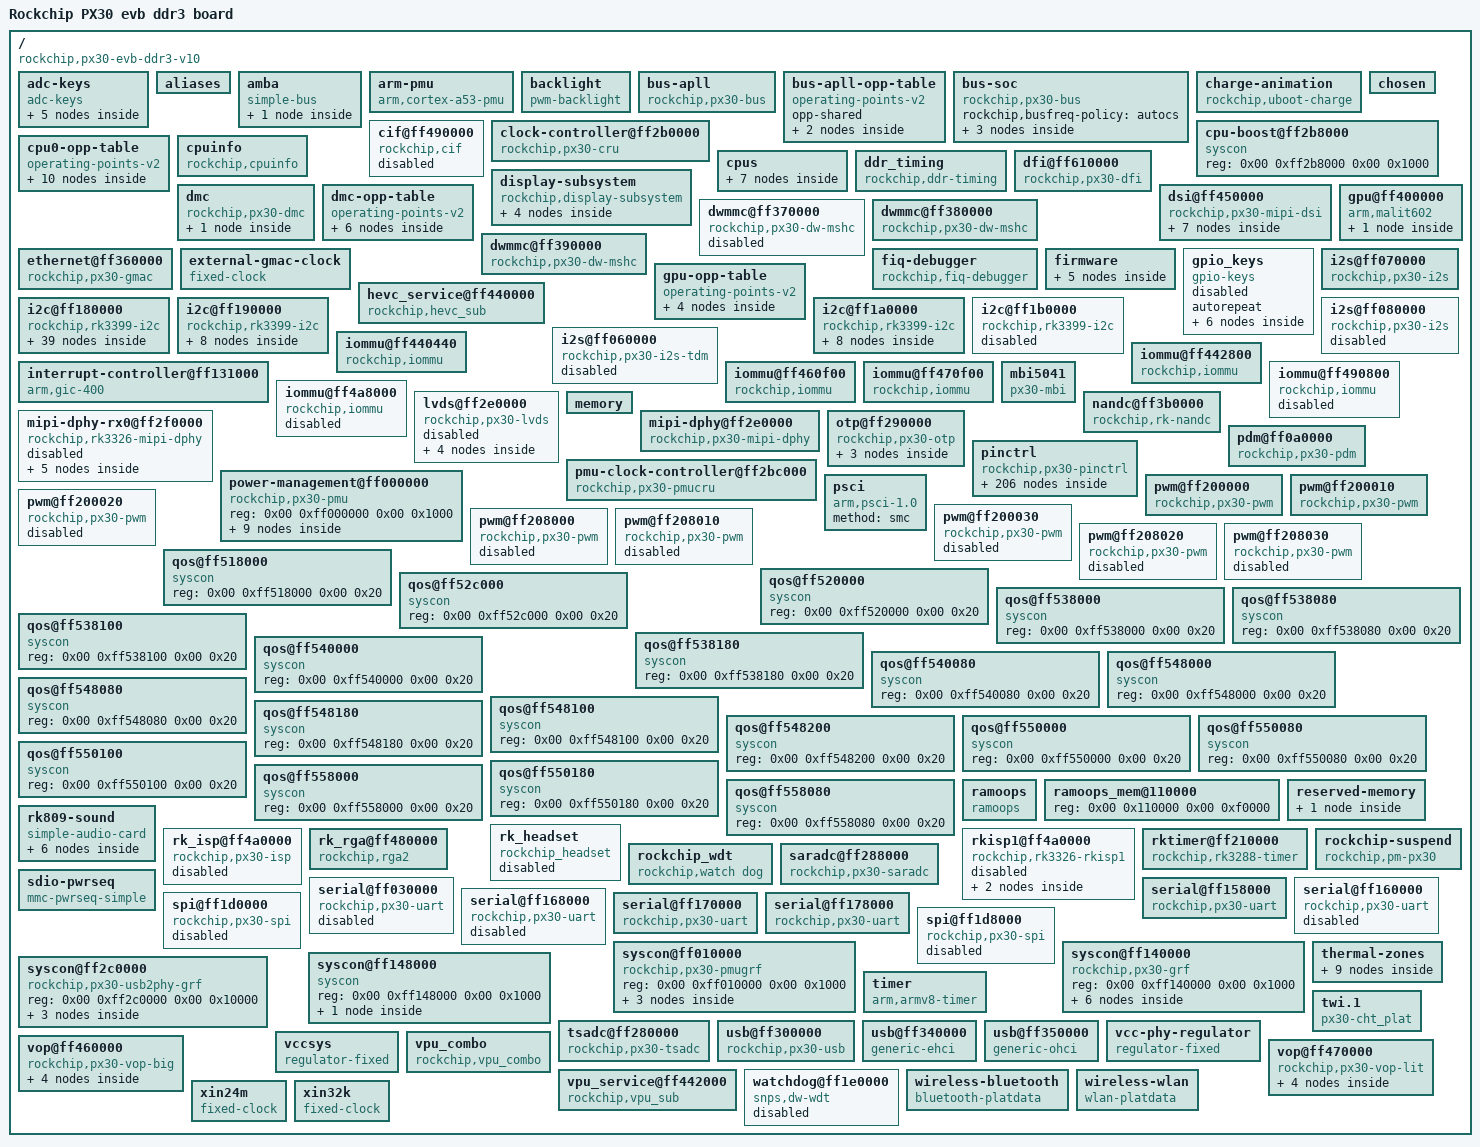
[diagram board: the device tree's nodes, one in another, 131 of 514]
/dts-v1/;

/memreserve/	0x0000000008081000 0x0000000000013000;
/memreserve/	0x0000000008097000 0x0000000000168978;
/ {
	#address-cells = <0x02>;
	#size-cells = <0x02>;
	compatible = "rockchip,px30-evb-ddr3-v10", "rockchip,px30";
	interrupt-parent = <0x01>;
	model = "Rockchip PX30 evb ddr3 board";
	serial-number = "XXXXXXXXXXXXXX";

	adc-keys {
		compatible = "adc-keys";
		io-channel-names = "buttons";
		io-channels = <0xc6 0x02>;
		keyup-threshold-microvolt = <0x1b7740>;
		poll-interval = <0x64>;

		esc-key {
			label = "esc";
			linux,code = <0x01>;
			press-threshold-microvolt = <0x13fd30>;
		};

		home-key {
			label = "home";
			linux,code = <0x66>;
			press-threshold-microvolt = <0x98580>;
		};

		menu-key {
			label = "menu";
			linux,code = <0x8b>;
			press-threshold-microvolt = <0xf0f78>;
		};

		vol-down-key {
			label = "volume down";
			linux,code = <0x72>;
			press-threshold-microvolt = <0x493e0>;
		};

		vol-up-key {
			label = "volume up";
			linux,code = <0x73>;
			press-threshold-microvolt = <0x4268>;
		};
	};

	aliases {
		ethernet0 = "/ethernet@ff360000";
		i2c0 = "/i2c@ff180000";
		i2c1 = "/i2c@ff190000";
		i2c2 = "/i2c@ff1a0000";
		i2c3 = "/i2c@ff1b0000";
		serial0 = "/serial@ff030000";
		serial1 = "/serial@ff158000";
		serial2 = "/serial@ff160000";
		serial3 = "/serial@ff168000";
		serial4 = "/serial@ff170000";
		serial5 = "/serial@ff178000";
		spi0 = "/spi@ff1d0000";
		spi1 = "/spi@ff1d8000";
	};

	amba {
		#address-cells = <0x02>;
		#size-cells = <0x02>;
		compatible = "simple-bus";
		ranges;

		dmac@ff240000 {
			#dma-cells = <0x01>;
			clock-names = "apb_pclk";
			clocks = <0x02 0xbb>;
			compatible = "arm,pl330", "arm,primecell";
			interrupts = <0x00 0x01 0x04 0x00 0x02 0x04>;
			peripherals-req-type-burst;
			phandle = <0x2c>;
			reg = <0x00 0xff240000 0x00 0x4000>;
		};
	};

	arm-pmu {
		compatible = "arm,cortex-a53-pmu";
		interrupt-affinity = <0x09 0x0a 0x0b 0x0c>;
		interrupts = <0x00 0x64 0x04 0x00 0x65 0x04 0x00 0x66 0x04 0x00 0x67 0x04>;
	};

	backlight {
		brightness-levels = <0x00 0x01 0x02 0x03 0x04 0x05 0x06 0x07 0x08 0x09 0x0a 0x0b 0x0c 0x0d 0x0e 0x0f 0x10 0x11 0x12 0x13 0x14 0x15 0x16 0x17 0x18 0x19 0x1a 0x1b 0x1c 0x1d 0x1e 0x1f 0x20 0x21 0x22 0x23 0x24 0x25 0x26 0x27 0x28 0x29 0x2a 0x2b 0x2c 0x2d 0x2e 0x2f 0x30 0x31 0x32 0x33 0x34 0x35 0x36 0x37 0x38 0x39 0x3a 0x3b 0x3c 0x3d 0x3e 0x3f 0x40 0x41 0x42 0x43 0x44 0x45 0x46 0x47 0x48 0x49 0x4a 0x4b 0x4c 0x4d 0x4e 0x4f 0x50 0x51 0x52 0x53 0x54 0x55 0x56 0x57 0x58 0x59 0x5a 0x5b 0x5c 0x5d 0x5e 0x5f 0x60 0x61 0x62 0x63 0x64 0x65 0x66 0x67 0x68 0x69 0x6a 0x6b 0x6c 0x6d 0x6e 0x6f 0x70 0x71 0x72 0x73 0x74 0x75 0x76 0x77 0x78 0x79 0x7a 0x7b 0x7c 0x7d 0x7e 0x7f 0x80 0x81 0x82 0x83 0x84 0x85 0x86 0x87 0x88 0x89 0x8a 0x8b 0x8c 0x8d 0x8e 0x8f 0x90 0x91 0x92 0x93 0x94 0x95 0x96 0x97 0x98 0x99 0x9a 0x9b 0x9c 0x9d 0x9e 0x9f 0xa0 0xa1 0xa2 0xa3 0xa4 0xa5 0xa6 0xa7 0xa8 0xa9 0xaa 0xab 0xac 0xad 0xae 0xaf 0xb0 0xb1 0xb2 0xb3 0xb4 0xb5 0xb6 0xb7 0xb8 0xb9 0xba 0xbb 0xbc 0xbd 0xbe 0xbf 0xc0 0xc1 0xc2 0xc3 0xc4 0xc5 0xc6 0xc7 0xc8 0xc9 0xca 0xcb 0xcc 0xcd 0xce 0xcf 0xd0 0xd1 0xd2 0xd3 0xd4 0xd5 0xd6 0xd7 0xd8 0xd9 0xda 0xdb 0xdc 0xdd 0xde 0xdf 0xe0 0xe1 0xe2 0xe3 0xe4 0xe5 0xe6 0xe7 0xe8 0xe9 0xea 0xeb 0xec 0xed 0xee 0xef 0xf0 0xf1 0xf2 0xf3 0xf4 0xf5 0xf6 0xf7 0xf8 0xf9 0xfa 0xfb 0xfc 0xfd 0xfe 0xff>;
		compatible = "pwm-backlight";
		default-brightness-level = <0x14>;
		phandle = <0xa5>;
		pwms = <0xc7 0x00 0x61a8 0x00>;
	};

	bus-apll {
		bus-supply = <0x0e>;
		clock-names = "bus";
		clocks = <0x02 0x01>;
		compatible = "rockchip,px30-bus";
		operating-points-v2 = <0x0d>;
		rockchip,busfreq-policy = "clkfreq";
		status = "okay";
	};

	bus-apll-opp-table {
		compatible = "operating-points-v2";
		opp-shared;
		phandle = <0x0d>;

		opp-1008000000 {
			opp-hz = <0x00 0x3c14dc00>;
			opp-microvolt = <0xe7ef0>;
		};

		opp-1512000000 {
			opp-hz = <0x00 0x5a1f4a00>;
			opp-microvolt = <0xf4240>;
		};
	};

	bus-soc {
		compatible = "rockchip,px30-bus";
		rockchip,busfreq-policy = "autocs";

		soc-bus0 {
			bus-id = <0x00>;
			enable-msk = <0x40f7>;
			status = "disabled";
			timer-us = <0x14>;
		};

		soc-bus1 {
			bus-id = <0x01>;
			enable-msk = <0x40bf>;
			status = "disabled";
			timer-us = <0xc8>;
		};

		soc-bus2 {
			bus-id = <0x02>;
			enable-msk = <0x4007>;
			status = "disabled";
			timer-us = <0xc8>;
		};
	};

	charge-animation {
		compatible = "rockchip,uboot-charge";
		rockchip,android-charge-on = <0x01>;
		rockchip,screen-on-voltage = <0xe10>;
		rockchip,uboot-charge-on = <0x00>;
		rockchip,uboot-low-power-voltage = <0xdac>;
		status = "okay";
	};

	chosen {
		bootargs = "storagemedia=emmc androidboot.mode=emmc androidboot.oem_unlocked=0 androidboot.slot_suffix= androidboot.serialno=XXXXXXXXXXXXXX buildvariant=userdebug loglevel=7 earlyprintk=uart8250,mmio32,0xff160000 swiotlb=1 console=ttyFIQ0 androidboot.baseband=N/A androidboot.veritymode=enforcing androidboot.hardware=rk30board androidboot.console=ttyFIQ0 init=/init kpti=0 androidboot.selinux=permissive";
		linux,initrd-end = <0x00 0x81ff978>;
		linux,initrd-start = <0x00 0x8097000>;
	};

	cif@ff490000 {
		clock-names = "aclk_cif0", "hclk_cif0", "pclk_cif", "cif0_out";
		clocks = <0x02 0xb3 0x02 0xf9 0x02 0x160 0x02 0x34>;
		compatible = "rockchip,cif";
		interrupts = <0x00 0x45 0x04>;
		iommus = <0xb0>;
		pinctrl-0 = <0xaf>;
		pinctrl-names = "cif_pin_all";
		power-domains = <0x8c 0x0d>;
		reg = <0x00 0xff490000 0x00 0x200>;
		reset-names = "rst_cif_a", "rst_cif_h", "rst_cif_pclkin";
		resets = <0x02 0x2c 0x02 0x2d 0x02 0x2e>;
		status = "disabled";
	};

	clock-controller@ff2b0000 {
		#clock-cells = <0x01>;
		#reset-cells = <0x01>;
		compatible = "rockchip,px30-cru";
		phandle = <0x02>;
		reg = <0x00 0xff2b0000 0x00 0x1000>;
		rockchip,boost = <0x8a>;
		rockchip,grf = <0x87>;
	};

	cpu-boost@ff2b8000 {
		compatible = "syscon";
		phandle = <0x8a>;
		reg = <0x00 0xff2b8000 0x00 0x1000>;
	};

	cpu0-opp-table {
		clocks = <0x02 0x01>;
		compatible = "operating-points-v2";
		nvmem-cell-names = "cpu_leakage", "performance";
		nvmem-cells = <0x07 0x08>;
		opp-shared;
		phandle = <0x03>;
		rockchip,avs = <0x01>;
		rockchip,avs-scale = <0x04>;
		rockchip,bin-scaling-sel = <0x00 0x0d 0x01 0x0f 0x02 0x12>;
		rockchip,evb-irdrop = <0x61a8>;
		rockchip,max-volt = <0x149970>;
		rockchip,pvtm-ch = <0x00 0x00>;
		rockchip,pvtm-error = <0x3e8>;
		rockchip,pvtm-freq = <0x639c0>;
		rockchip,pvtm-number = <0x0a>;
		rockchip,pvtm-ref-temp = <0x28>;
		rockchip,pvtm-sample-time = <0x3e8>;
		rockchip,pvtm-temp-prop = <0xffffffc8 0xffffffc8>;
		rockchip,pvtm-volt = <0xf4240>;
		rockchip,pvtm-voltage-sel = <0x00 0xc350 0x00 0xc351 0xd2f0 0x01 0xd2f1 0xea60 0x02 0xea61 0x1869f 0x03>;
		rockchip,thermal-zone = "soc-thermal";

		opp-1008000000 {
			clock-latency-ns = <0x9c40>;
			opp-hz = <0x00 0x3c14dc00>;
			opp-microvolt = <0x11edd8 0x11edd8 0x149970>;
			opp-microvolt-L0 = <0x11edd8 0x11edd8 0x149970>;
			opp-microvolt-L1 = <0x112a88 0x112a88 0x149970>;
			opp-microvolt-L2 = <0x112a88 0x112a88 0x149970>;
			opp-microvolt-L3 = <0x100590 0x100590 0x149970>;
		};

		opp-1104000000 {
			clock-latency-ns = <0x9c40>;
			opp-hz = <0x00 0x41cdb400>;
			opp-microvolt = <0x13d620 0x13d620 0x149970>;
			opp-microvolt-L0 = <0x13d620 0x13d620 0x149970>;
			opp-microvolt-L1 = <0x137478 0x137478 0x149970>;
			opp-microvolt-L2 = <0x1312d0 0x1312d0 0x149970>;
			opp-microvolt-L3 = <0x124f80 0x124f80 0x149970>;
		};

		opp-1200000000 {
			clock-latency-ns = <0x9c40>;
			opp-hz = <0x00 0x47868c00>;
			opp-microvolt = <0x13d620 0x13d620 0x149970>;
			opp-microvolt-L0 = <0x13d620 0x13d620 0x149970>;
			opp-microvolt-L1 = <0x137478 0x137478 0x149970>;
			opp-microvolt-L2 = <0x1312d0 0x1312d0 0x149970>;
			opp-microvolt-L3 = <0x124f80 0x124f80 0x149970>;
		};

		opp-1248000000 {
			clock-latency-ns = <0x9c40>;
			opp-hz = <0x00 0x4a62f800>;
			opp-microvolt = <0x149970 0x149970 0x149970>;
			opp-microvolt-L0 = <0x149970 0x149970 0x149970>;
			opp-microvolt-L1 = <0x13d620 0x13d620 0x149970>;
			opp-microvolt-L2 = <0x137478 0x137478 0x149970>;
			opp-microvolt-L3 = <0x12b128 0x12b128 0x149970>;
		};

		opp-1296000000 {
			clock-latency-ns = <0x9c40>;
			opp-hz = <0x00 0x4d3f6400>;
			opp-microvolt = <0x149970 0x149970 0x149970>;
			opp-microvolt-L0 = <0x149970 0x149970 0x149970>;
			opp-microvolt-L1 = <0x149970 0x149970 0x149970>;
			opp-microvolt-L2 = <0x13d620 0x13d620 0x149970>;
			opp-microvolt-L3 = <0x1312d0 0x1312d0 0x149970>;
		};

		opp-1416000000 {
			clock-latency-ns = <0x9c40>;
			opp-hz = <0x00 0x54667200>;
			opp-microvolt = <0x149970 0x149970 0x149970>;
			opp-microvolt-L0 = <0x149970 0x149970 0x149970>;
			opp-microvolt-L1 = <0x149970 0x149970 0x149970>;
			opp-microvolt-L2 = <0x13d620 0x13d620 0x149970>;
			opp-microvolt-L3 = <0x1312d0 0x1312d0 0x149970>;
		};

		opp-1512000000 {
			clock-latency-ns = <0x9c40>;
			opp-hz = <0x00 0x5a1f4a00>;
			opp-microvolt = <0x149970 0x149970 0x149970>;
			opp-microvolt-L0 = <0x149970 0x149970 0x149970>;
			opp-microvolt-L1 = <0x149970 0x149970 0x149970>;
			opp-microvolt-L2 = <0x13d620 0x13d620 0x149970>;
			opp-microvolt-L3 = <0x1312d0 0x1312d0 0x149970>;
		};

		opp-408000000 {
			clock-latency-ns = <0x9c40>;
			opp-hz = <0x00 0x18519600>;
			opp-microvolt = <0xe7ef0 0xe7ef0 0x149970>;
			opp-microvolt-L0 = <0xe7ef0 0xe7ef0 0x149970>;
			opp-microvolt-L1 = <0xe7ef0 0xe7ef0 0x149970>;
			opp-microvolt-L2 = <0xe7ef0 0xe7ef0 0x149970>;
			opp-microvolt-L3 = <0xe7ef0 0xe7ef0 0x149970>;
			opp-suspend;
		};

		opp-600000000 {
			clock-latency-ns = <0x9c40>;
			opp-hz = <0x00 0x23c34600>;
			opp-microvolt = <0xe7ef0 0xe7ef0 0x149970>;
			opp-microvolt-L0 = <0xe7ef0 0xe7ef0 0x149970>;
			opp-microvolt-L1 = <0xe7ef0 0xe7ef0 0x149970>;
			opp-microvolt-L2 = <0xe7ef0 0xe7ef0 0x149970>;
			opp-microvolt-L3 = <0xe7ef0 0xe7ef0 0x149970>;
		};

		opp-816000000 {
			clock-latency-ns = <0x9c40>;
			opp-hz = <0x00 0x30a32c00>;
			opp-microvolt = <0x100590 0x100590 0x149970>;
			opp-microvolt-L0 = <0x100590 0x100590 0x149970>;
			opp-microvolt-L1 = <0xf4240 0xf4240 0x149970>;
			opp-microvolt-L2 = <0xf4240 0xf4240 0x149970>;
			opp-microvolt-L3 = <0xe7ef0 0xe7ef0 0x149970>;
		};
	};

	cpuinfo {
		compatible = "rockchip,cpuinfo";
		nvmem-cell-names = "id";
		nvmem-cells = <0x0f>;
	};

	cpus {
		#address-cells = <0x02>;
		#size-cells = <0x00>;

		cpu@0 {
			#cooling-cells = <0x02>;
			clocks = <0x02 0x07>;
			compatible = "arm,cortex-a35", "arm,armv8";
			cpu-idle-states = <0x04 0x05>;
			cpu-supply = <0x06>;
			device_type = "cpu";
			dynamic-power-coefficient = <0x5a>;
			enable-method = "psci";
			operating-points-v2 = <0x03>;
			phandle = <0x09>;
			reg = <0x00 0x00>;
		};

		cpu@1 {
			compatible = "arm,cortex-a35", "arm,armv8";
			cpu-idle-states = <0x04 0x05>;
			device_type = "cpu";
			enable-method = "psci";
			operating-points-v2 = <0x03>;
			phandle = <0x0a>;
			reg = <0x00 0x01>;
		};

		cpu@2 {
			compatible = "arm,cortex-a35", "arm,armv8";
			cpu-idle-states = <0x04 0x05>;
			device_type = "cpu";
			enable-method = "psci";
			operating-points-v2 = <0x03>;
			phandle = <0x0b>;
			reg = <0x00 0x02>;
		};

		cpu@3 {
			compatible = "arm,cortex-a35", "arm,armv8";
			cpu-idle-states = <0x04 0x05>;
			device_type = "cpu";
			enable-method = "psci";
			operating-points-v2 = <0x03>;
			phandle = <0x0c>;
			reg = <0x00 0x03>;
		};

		idle-states {
			entry-method = "psci";

			cluster-sleep {
				arm,psci-suspend-param = <0x1010000>;
				compatible = "arm,idle-state";
				entry-latency-us = <0x190>;
				exit-latency-us = <0x1f4>;
				local-timer-stop;
				min-residency-us = <0x7d0>;
				phandle = <0x05>;
			};

			cpu-sleep {
				arm,psci-suspend-param = <0x10000>;
				compatible = "arm,idle-state";
				entry-latency-us = <0x78>;
				exit-latency-us = <0xfa>;
				local-timer-stop;
				min-residency-us = <0x384>;
				phandle = <0x04>;
			};
		};
	};

	ddr_timing {
		auto_pd_dis_freq = <0x42a>;
		auto_sr_dis_freq = <0x320>;
		compatible = "rockchip,ddr-timing";
		cs0_dm0_rx_de-skew = <0x07>;
		cs0_dm0_tx_de-skew = <0x07>;
		cs0_dm1_rx_de-skew = <0x07>;
		cs0_dm1_tx_de-skew = <0x06>;
		cs0_dm2_rx_de-skew = <0x07>;
		cs0_dm2_tx_de-skew = <0x07>;
		cs0_dm3_rx_de-skew = <0x07>;
		cs0_dm3_tx_de-skew = <0x07>;
		cs0_dq0_rx_de-skew = <0x08>;
		cs0_dq0_tx_de-skew = <0x08>;
		cs0_dq10_rx_de-skew = <0x08>;
		cs0_dq10_tx_de-skew = <0x08>;
		cs0_dq11_rx_de-skew = <0x08>;
		cs0_dq11_tx_de-skew = <0x07>;
		cs0_dq12_rx_de-skew = <0x08>;
		cs0_dq12_tx_de-skew = <0x08>;
		cs0_dq13_rx_de-skew = <0x09>;
		cs0_dq13_tx_de-skew = <0x07>;
		cs0_dq14_rx_de-skew = <0x09>;
		cs0_dq14_tx_de-skew = <0x08>;
		cs0_dq15_rx_de-skew = <0x09>;
		cs0_dq15_tx_de-skew = <0x07>;
		cs0_dq16_rx_de-skew = <0x09>;
		cs0_dq16_tx_de-skew = <0x09>;
		cs0_dq17_rx_de-skew = <0x07>;
		cs0_dq17_tx_de-skew = <0x09>;
		cs0_dq18_rx_de-skew = <0x07>;
		cs0_dq18_tx_de-skew = <0x08>;
		cs0_dq19_rx_de-skew = <0x07>;
		cs0_dq19_tx_de-skew = <0x09>;
		cs0_dq1_rx_de-skew = <0x09>;
		cs0_dq1_tx_de-skew = <0x08>;
		cs0_dq20_rx_de-skew = <0x09>;
		cs0_dq20_tx_de-skew = <0x09>;
		cs0_dq21_rx_de-skew = <0x09>;
		cs0_dq21_tx_de-skew = <0x09>;
		cs0_dq22_rx_de-skew = <0x08>;
		cs0_dq22_tx_de-skew = <0x09>;
		cs0_dq23_rx_de-skew = <0x08>;
		cs0_dq23_tx_de-skew = <0x09>;
		cs0_dq24_rx_de-skew = <0x08>;
		cs0_dq24_tx_de-skew = <0x08>;
		cs0_dq25_rx_de-skew = <0x09>;
		cs0_dq25_tx_de-skew = <0x09>;
		cs0_dq26_rx_de-skew = <0x09>;
		cs0_dq26_tx_de-skew = <0x08>;
		cs0_dq27_rx_de-skew = <0x09>;
		cs0_dq27_tx_de-skew = <0x08>;
		cs0_dq28_rx_de-skew = <0x09>;
		cs0_dq28_tx_de-skew = <0x09>;
		cs0_dq29_rx_de-skew = <0x09>;
		cs0_dq29_tx_de-skew = <0x09>;
		cs0_dq2_rx_de-skew = <0x08>;
		cs0_dq2_tx_de-skew = <0x08>;
		cs0_dq30_rx_de-skew = <0x08>;
		cs0_dq30_tx_de-skew = <0x08>;
		cs0_dq31_rx_de-skew = <0x08>;
		cs0_dq31_tx_de-skew = <0x08>;
		cs0_dq3_rx_de-skew = <0x08>;
		cs0_dq3_tx_de-skew = <0x08>;
		cs0_dq4_rx_de-skew = <0x09>;
		cs0_dq4_tx_de-skew = <0x08>;
		cs0_dq5_rx_de-skew = <0x09>;
		cs0_dq5_tx_de-skew = <0x08>;
		cs0_dq6_rx_de-skew = <0x09>;
		cs0_dq6_tx_de-skew = <0x08>;
		cs0_dq7_rx_de-skew = <0x08>;
		cs0_dq7_tx_de-skew = <0x08>;
		cs0_dq8_rx_de-skew = <0x08>;
		cs0_dq8_tx_de-skew = <0x07>;
		cs0_dq9_rx_de-skew = <0x09>;
		cs0_dq9_tx_de-skew = <0x07>;
		cs0_dqs0_rx_de-skew = <0x06>;
		cs0_dqs0n_tx_de-skew = <0x09>;
		cs0_dqs0p_tx_de-skew = <0x09>;
		cs0_dqs1_rx_de-skew = <0x07>;
		cs0_dqs1n_tx_de-skew = <0x09>;
		cs0_dqs1p_tx_de-skew = <0x09>;
		cs0_dqs2_rx_de-skew = <0x06>;
		cs0_dqs2n_tx_de-skew = <0x09>;
		cs0_dqs2p_tx_de-skew = <0x09>;
		cs0_dqs3_rx_de-skew = <0x07>;
		cs0_dqs3n_tx_de-skew = <0x09>;
		cs0_dqs3p_tx_de-skew = <0x09>;
		cs1_dm0_rx_de-skew = <0x07>;
		cs1_dm0_tx_de-skew = <0x07>;
		cs1_dm1_rx_de-skew = <0x07>;
		cs1_dm1_tx_de-skew = <0x07>;
		cs1_dm2_rx_de-skew = <0x07>;
		cs1_dm2_tx_de-skew = <0x08>;
		cs1_dm3_rx_de-skew = <0x07>;
		cs1_dm3_tx_de-skew = <0x07>;
		cs1_dq0_rx_de-skew = <0x08>;
		cs1_dq0_tx_de-skew = <0x08>;
		cs1_dq10_rx_de-skew = <0x07>;
		cs1_dq10_tx_de-skew = <0x08>;
		cs1_dq11_rx_de-skew = <0x08>;
		cs1_dq11_tx_de-skew = <0x08>;
		cs1_dq12_rx_de-skew = <0x08>;
		cs1_dq12_tx_de-skew = <0x07>;
		cs1_dq13_rx_de-skew = <0x08>;
		cs1_dq13_tx_de-skew = <0x08>;
		cs1_dq14_rx_de-skew = <0x08>;
		cs1_dq14_tx_de-skew = <0x08>;
		cs1_dq15_rx_de-skew = <0x08>;
		cs1_dq15_tx_de-skew = <0x07>;
		cs1_dq16_rx_de-skew = <0x08>;
		cs1_dq16_tx_de-skew = <0x09>;
		cs1_dq17_rx_de-skew = <0x08>;
		cs1_dq17_tx_de-skew = <0x09>;
		cs1_dq18_rx_de-skew = <0x07>;
		cs1_dq18_tx_de-skew = <0x08>;
		cs1_dq19_rx_de-skew = <0x08>;
		cs1_dq19_tx_de-skew = <0x09>;
		cs1_dq1_rx_de-skew = <0x09>;
		cs1_dq1_tx_de-skew = <0x08>;
		cs1_dq20_rx_de-skew = <0x09>;
		cs1_dq20_tx_de-skew = <0x09>;
		cs1_dq21_rx_de-skew = <0x09>;
		cs1_dq21_tx_de-skew = <0x09>;
		cs1_dq22_rx_de-skew = <0x08>;
		cs1_dq22_tx_de-skew = <0x09>;
		cs1_dq23_rx_de-skew = <0x08>;
		cs1_dq23_tx_de-skew = <0x09>;
		cs1_dq24_rx_de-skew = <0x08>;
		cs1_dq24_tx_de-skew = <0x09>;
		cs1_dq25_rx_de-skew = <0x09>;
		cs1_dq25_tx_de-skew = <0x09>;
		cs1_dq26_rx_de-skew = <0x09>;
		cs1_dq26_tx_de-skew = <0x08>;
		cs1_dq27_rx_de-skew = <0x08>;
		cs1_dq27_tx_de-skew = <0x08>;
		cs1_dq28_rx_de-skew = <0x09>;
		cs1_dq28_tx_de-skew = <0x09>;
		cs1_dq29_rx_de-skew = <0x09>;
		cs1_dq29_tx_de-skew = <0x09>;
		cs1_dq2_rx_de-skew = <0x08>;
		cs1_dq2_tx_de-skew = <0x08>;
		cs1_dq30_rx_de-skew = <0x09>;
		cs1_dq30_tx_de-skew = <0x08>;
		cs1_dq31_rx_de-skew = <0x08>;
		cs1_dq31_tx_de-skew = <0x08>;
		cs1_dq3_rx_de-skew = <0x08>;
		cs1_dq3_tx_de-skew = <0x08>;
		cs1_dq4_rx_de-skew = <0x08>;
		cs1_dq4_tx_de-skew = <0x08>;
		cs1_dq5_rx_de-skew = <0x09>;
		cs1_dq5_tx_de-skew = <0x08>;
		cs1_dq6_rx_de-skew = <0x09>;
		cs1_dq6_tx_de-skew = <0x08>;
		cs1_dq7_rx_de-skew = <0x08>;
		cs1_dq7_tx_de-skew = <0x08>;
		cs1_dq8_rx_de-skew = <0x08>;
		cs1_dq8_tx_de-skew = <0x08>;
		cs1_dq9_rx_de-skew = <0x08>;
		cs1_dq9_tx_de-skew = <0x07>;
		cs1_dqs0_rx_de-skew = <0x06>;
		cs1_dqs0n_tx_de-skew = <0x09>;
		cs1_dqs0p_tx_de-skew = <0x09>;
		cs1_dqs1_rx_de-skew = <0x07>;
		cs1_dqs1n_tx_de-skew = <0x09>;
		cs1_dqs1p_tx_de-skew = <0x09>;
		cs1_dqs2_rx_de-skew = <0x06>;
		cs1_dqs2n_tx_de-skew = <0x09>;
		cs1_dqs2p_tx_de-skew = <0x09>;
		cs1_dqs3_rx_de-skew = <0x07>;
		cs1_dqs3n_tx_de-skew = <0x09>;
		cs1_dqs3p_tx_de-skew = <0x09>;
		ddr2_dll_dis_freq = <0x12c>;
		ddr2_drv = <0x01>;
		ddr2_odt = <0x96>;
		ddr2_odt_dis_freq = <0x64>;
		ddr2_speed_bin = <0x00>;
		ddr3_dll_dis_freq = <0x12c>;
		ddr3_drv = <0x28>;
		ddr3_odt = <0x78>;
		ddr3_odt_dis_freq = <0x190>;
		ddr3_speed_bin = <0x15>;
		ddr3a0_ddr4a10_de-skew = <0x07>;
		ddr3a10_ddr4cs0_de-skew = <0x07>;
		ddr3a11_ddr4a3_de-skew = <0x07>;
		ddr3a12_ddr4ba1_de-skew = <0x07>;
		ddr3a13_ddr4a2_de-skew = <0x07>;
		ddr3a14_ddr4a1_de-skew = <0x07>;
		ddr3a15_ddr4odt0_de-skew = <0x07>;
		ddr3a1_ddr4a9_de-skew = <0x06>;
		ddr3a2_ddr4a4_de-skew = <0x07>;
		ddr3a3_ddr4a6_de-skew = <0x07>;
		ddr3a4_ddr4a5_de-skew = <0x07>;
		ddr3a5_ddr4a8_de-skew = <0x07>;
		ddr3a6_ddr4a7_de-skew = <0x06>;
		ddr3a7_ddr4a11_de-skew = <0x07>;
		ddr3a8_ddr4a13_de-skew = <0x07>;
		ddr3a9_ddr4a0_de-skew = <0x07>;
		ddr3ba0_ddr4bg0_de-skew = <0x07>;
		ddr3ba1_ddr4a15_de-skew = <0x07>;
		ddr3ba2_ddr4ba0_de-skew = <0x07>;
		ddr3cas_ddr4a12_de-skew = <0x07>;
		ddr3cke_ddr4a16_de-skew = <0x07>;
		ddr3ckn_ddr4ckn_de-skew = <0x07>;
		ddr3ckp_ddr4ckp_de-skew = <0x07>;
		ddr3cs0_ddr4act_de-skew = <0x06>;
		ddr3cs1_ddr4cs1_de-skew = <0x06>;
		ddr3odt0_ddr4a14_de-skew = <0x07>;
		ddr3odt1_ddr4odt1_de-skew = <0x07>;
		ddr3ras_ddr4cke_de-skew = <0x07>;
		ddr3reset_ddr4reset_de-skew = <0x07>;
		ddr3we_ddr4bg1_de-skew = <0x07>;
		ddr4_dll_dis_freq = <0x271>;
		ddr4_drv = <0x22>;
		ddr4_odt = <0xf0>;
		ddr4_odt_dis_freq = <0x29a>;
		ddr4_speed_bin = <0x0c>;
		lpddr2_drv = <0x28>;
		lpddr3_drv = <0x28>;
		lpddr3_odt = <0xf0>;
		lpddr3_odt_dis_freq = <0x190>;
		lpddr4_ca_odt = <0x28>;
		lpddr4_dq_odt = <0x28>;
		lpddr4_drv = <0x3c>;
		lpddr4_odt_dis_freq = <0x320>;
		pd_idle = <0x0d>;
		phandle = <0xb9>;
		phy_ddr2_ca_drv = <0x15>;
		phy_ddr2_ck_drv = <0x12>;
		phy_ddr2_dq_drv = <0x15>;
		phy_ddr2_odt = <0x02>;
		phy_ddr2_odt_dis_freq = <0x64>;
		phy_ddr3_ca_drv = <0x15>;
		phy_ddr3_ck_drv = <0x12>;
		phy_ddr3_dq_drv = <0x15>;
		phy_ddr3_odt = <0x04>;
		phy_ddr3_odt_dis_freq = <0x190>;
		phy_ddr4_ca_drv = <0x16>;
		phy_ddr4_ck_drv = <0x13>;
		phy_ddr4_dq_drv = <0x16>;
		phy_ddr4_odt = <0x02>;
		phy_ddr4_odt_dis_freq = <0x29a>;
		phy_dll_dis_freq = <0x190>;
		phy_lpddr2_ca_drv = <0x16>;
		phy_lpddr2_ck_drv = <0x13>;
		phy_lpddr2_dq_drv = <0x16>;
		phy_lpddr2_odt = <0x00>;
		phy_lpddr2_odt_dis_freq = <0x29a>;
		phy_lpddr3_ca_drv = <0x16>;
		phy_lpddr3_ck_drv = <0x13>;
		phy_lpddr3_dq_drv = <0x16>;
		phy_lpddr3_odt = <0x02>;
		phy_lpddr3_odt_dis_freq = <0x190>;
		phy_lpddr4_ca_drv = <0x14>;
		phy_lpddr4_ck_cs_drv = <0x06>;
		phy_lpddr4_dq_drv = <0x06>;
		phy_lpddr4_odt = <0x10>;
		phy_lpddr4_odt_dis_freq = <0x320>;
		sr_idle = <0x5d>;
		sr_mc_gate_idle = <0x00>;
		srpd_lite_idle = <0x00>;
		standby_idle = <0x00>;
	};

	dfi@ff610000 {
		compatible = "rockchip,px30-dfi";
		phandle = <0xb7>;
		reg = <0x00 0xff610000 0x00 0x400>;
		rockchip,pmugrf = <0xb6>;
		status = "okay";
	};

	display-subsystem {
		compatible = "rockchip,display-subsystem";
		logo-memory-region = <0x12>;
		ports = <0x10 0x11>;
		status = "okay";

		route {

			route-dsi {
				charge_logo,mode = "center";
				connect = <0x14>;
				logo,bpp = <0x10>;
				logo,height = <0x1e0>;
				logo,kernel = "logo_kernel.bmp";
				logo,mode = "center";
				logo,offset = <0x39000>;
				logo,uboot = "logo.bmp";
				logo,width = <0x1e0>;
				logo,ymirror = <0x00>;
				overscan,bottom_margin = <0x64>;
				overscan,left_margin = <0x64>;
				overscan,right_margin = <0x64>;
				overscan,top_margin = <0x64>;
				status = "okay";
				video,crtc_hsync_end = <0x1f6>;
				video,crtc_vsync_end = <0x1f4>;
				video,flags = <0x0a>;
				video,hdisplay = <0x1e0>;
				video,vdisplay = <0x1e0>;
				video,vrefresh = <0x3c>;
			};

			route-lvds {
				charge_logo,mode = "center";
				connect = <0x13>;
				logo,kernel = "logo_kernel.bmp";
				logo,mode = "center";
				logo,uboot = "logo.bmp";
				status = "disabled";
			};

			route-rgb {
				charge_logo,mode = "center";
				connect = <0x15>;
				logo,kernel = "logo_kernel.bmp";
				logo,mode = "center";
				logo,uboot = "logo.bmp";
				status = "disabled";
			};
		};
	};

	dmc {
		#cooling-cells = <0x02>;
		auto-freq-en = <0x01>;
		auto-min-freq = <0x50140>;
		center-supply = <0x0e>;
		clock-names = "dmc_clk";
		clocks = <0x02 0x54>;
		compatible = "rockchip,px30-dmc";
		ddr_timing = <0xb9>;
		devfreq-events = <0xb7>;
		downdifferential = <0x14>;
		interrupt-names = "complete_irq";
		interrupts = <0x00 0x69 0x04>;
		operating-points-v2 = <0xb8>;
		phandle = <0xb4>;
		status = "okay";
		system-status-freq = <0x01 0x80e80 0x08 0x6ddd0 0x02 0x2f5d0 0x20 0x6ddd0 0x1000 0x80e80 0x4000 0xa2990 0x2000 0xa2990>;
		upthreshold = <0x28>;

		ddr_power_model {
			compatible = "ddr_power_model";
			dynamic-power-coefficient = <0x78>;
			static-power-coefficient = <0xc8>;
			thermal-zone = "soc-thermal";
			ts = <0x7d00 0x125c 0xffffffb0 0x02>;
		};
	};

	dmc-opp-table {
		compatible = "operating-points-v2";
		phandle = <0xb8>;
		rockchip,evb-irdrop = <0x61a8>;
		rockchip,max-volt = <0x118c30>;
		rockchip,pvtm-ch = <0x00 0x00>;
		rockchip,pvtm-voltage-sel = <0x00 0xc350 0x00 0xc351 0xd2f0 0x01 0xd2f1 0xea60 0x02 0xea61 0x1869f 0x03>;

		opp-194000000 {
			opp-hz = <0x00 0xb903480>;
			opp-microvolt = <0xe7ef0>;
			opp-microvolt-L0 = <0xe7ef0>;
			opp-microvolt-L1 = <0xe7ef0>;
			opp-microvolt-L2 = <0xe7ef0>;
			opp-microvolt-L3 = <0xe7ef0>;
		};

		opp-328000000 {
			opp-hz = <0x00 0x138ce200>;
			opp-microvolt = <0xe7ef0>;
			opp-microvolt-L0 = <0xe7ef0>;
			opp-microvolt-L1 = <0xe7ef0>;
			opp-microvolt-L2 = <0xe7ef0>;
			opp-microvolt-L3 = <0xe7ef0>;
		};

		opp-450000000 {
			opp-hz = <0x00 0x1ad27480>;
			opp-microvolt = <0xe7ef0>;
			opp-microvolt-L0 = <0xe7ef0>;
			opp-microvolt-L1 = <0xe7ef0>;
			opp-microvolt-L2 = <0xe7ef0>;
			opp-microvolt-L3 = <0xe7ef0>;
		};

		opp-528000000 {
			opp-hz = <0x00 0x1f78a400>;
			opp-microvolt = <0xee098>;
			opp-microvolt-L0 = <0xee098>;
			opp-microvolt-L1 = <0xee098>;
			opp-microvolt-L2 = <0xe7ef0>;
			opp-microvolt-L3 = <0xe7ef0>;
		};

		opp-666000000 {
			opp-hz = <0x00 0x27b25a80>;
			opp-microvolt = <0x100590>;
			opp-microvolt-L0 = <0x100590>;
			opp-microvolt-L1 = <0xf4240>;
			opp-microvolt-L2 = <0xee098>;
			opp-microvolt-L3 = <0xe7ef0>;
			status = "disabled";
		};

		opp-786000000 {
			opp-hz = <0x00 0x2ed96880>;
			opp-microvolt = <0x10c8e0>;
			opp-microvolt-L0 = <0x10c8e0>;
			opp-microvolt-L1 = <0x100590>;
			opp-microvolt-L2 = <0xfa3e8>;
			opp-microvolt-L3 = <0xf4240>;
			status = "disabled";
		};
	};

	dsi@ff450000 {
		#address-cells = <0x01>;
		#size-cells = <0x00>;
		clock-names = "pclk", "hs_clk";
		clocks = <0x02 0x144 0xa3>;
		compatible = "rockchip,px30-mipi-dsi";
		interrupts = <0x00 0x4b 0x04>;
		phy-names = "mipi_dphy";
		phys = <0xa3>;
		power-domains = <0x8c 0x0c>;
		reg = <0x00 0xff450000 0x00 0x10000>;
		reset-names = "apb";
		resets = <0x02 0x3d>;
		rockchip,grf = <0x87>;
		rockchip,lane-rate = <0xd5>;
		status = "okay";

		panel@0 {
			backlight = <0xa5>;
			compatible = "simple-panel-dsi";
			disable-delay-ms = <0x14>;
			dsi,flags = <0x803>;
			dsi,format = <0x00>;
			dsi,lanes = <0x02>;
			enable-delay-ms = <0x28>;
			height-mm = <0x46>;
			init-delay-ms = <0x14>;
			panel-exit-sequence = <0x5000128 0x5780110>;
			panel-init-sequence = [39 00 06 ff 77 01 00 00 10 39 00 03 c0 3b 00 39 00 03 c1 0d 02 39 00 03 c2 21 08 39 00 11 b0 00 11 18 0e 11 06 07 08 07 22 04 12 0f aa 31 18 39 00 11 b1 00 11 19 0e 12 07 08 08 08 22 04 11 11 a9 32 18 39 00 06 ff 77 01 00 00 11 15 00 02 b0 60 15 00 02 b1 30 15 00 02 b2 87 15 00 02 b3 80 15 00 02 b5 49 15 00 02 b7 85 15 00 02 b8 21 15 00 02 c1 78 15 14 02 c2 78 39 00 04 e0 00 1b 02 39 00 0c e1 08 a0 00 00 07 a0 00 00 00 44 44 39 00 0d e2 11 11 44 44 ed a0 00 00 ec a0 00 00 39 00 05 e3 00 00 11 11 39 00 03 e4 44 44 39 00 11 e5 0a e9 d8 a0 0c eb d8 a0 0e ed d8 a0 10 ef d8 a0 39 00 05 e6 00 00 11 11 39 00 03 e7 44 44 39 00 11 e8 09 e8 d8 a0 0b ea d8 a0 0d ec d8 a0 0f ee d8 a0 39 00 08 eb 02 00 e4 e4 88 00 40 39 00 03 ec 3c 00 39 00 11 ed ab 89 76 54 02 ff ff ff ff ff ff 20 45 67 98 ba 39 00 06 ff 77 01 00 00 00 05 78 01 11 05 78 01 29];
			power-supply = <0x66>;
			prepare-delay-ms = <0x14>;
			reg = <0x00>;
			reset-delay-ms = <0x14>;
			reset-gpios = <0x67 0x00 0x01>;
			status = "okay";
			unprepare-delay-ms = <0x14>;
			width-mm = <0x48>;

			display-timings {
				native-mode = <0xa6>;

				timing0 {
					clock-frequency = <0xf42400>;
					de-active = <0x00>;
					hactive = <0x1e0>;
					hback-porch = <0x0f>;
					hfront-porch = <0x0c>;
					hsync-active = <0x00>;
					hsync-len = <0x0a>;
					phandle = <0xa6>;
					pixelclk-active = <0x00>;
					vactive = <0x1e0>;
					vback-porch = <0x0f>;
					vfront-porch = <0x0c>;
					vsync-active = <0x00>;
					vsync-len = <0x08>;
				};
			};
		};

		ports {

			port {
				#address-cells = <0x01>;
				#size-cells = <0x00>;

				endpoint@0 {
					phandle = <0xa9>;
					reg = <0x00>;
					remote-endpoint = <0x14>;
				};

				endpoint@1 {
					phandle = <0xad>;
					reg = <0x01>;
					remote-endpoint = <0xa4>;
					status = "disabled";
				};
			};
		};
	};

	dwmmc@ff370000 {
		assigned-clock-parents = <0x02 0x57>;
		assigned-clocks = <0x02 0x3b>;
		bus-width = <0x04>;
		cap-mmc-highspeed;
		cap-sd-highspeed;
		cap-sdio-irq;
		card-detect-delay = <0x320>;
		clock-names = "biu", "ciu", "ciu-drv", "ciu-sample";
		clocks = <0x02 0xf7 0x02 0x3b 0x02 0x43 0x02 0x44>;
		compatible = "rockchip,px30-dw-mshc", "rockchip,rk3288-dw-mshc";
		fifo-depth = <0x100>;
		ignore-pm-notify;
		interrupts = <0x00 0x36 0x04>;
		max-frequency = <0x8f0d180>;
		pinctrl-0 = <0x95 0x96 0x97 0x98>;
		pinctrl-names = "default";
		power-domains = <0x8c 0x07>;
		reg = <0x00 0xff370000 0x00 0x4000>;
		sd-uhs-sdr104;
		sd-uhs-sdr12;
		sd-uhs-sdr25;
		sd-uhs-sdr50;
		status = "disabled";
		supports-sd;
		vmmc-supply = <0x99>;
		vqmmc-supply = <0x4a>;
	};

	dwmmc@ff380000 {
		assigned-clock-parents = <0x02 0x51>;
		assigned-clocks = <0x02 0x38>;
		bus-width = <0x04>;
		cap-sd-highspeed;
		cap-sdio-irq;
		clock-names = "biu", "ciu", "ciu-drv", "ciu-sample";
		clocks = <0x02 0xff 0x02 0x38 0x02 0x45 0x02 0x46>;
		compatible = "rockchip,px30-dw-mshc", "rockchip,rk3288-dw-mshc";
		fifo-depth = <0x100>;
		ignore-pm-notify;
		interrupts = <0x00 0x37 0x04>;
		keep-power-in-suspend;
		max-frequency = <0x8f0d180>;
		mmc-pwrseq = <0x9d>;
		non-removable;
		pinctrl-0 = <0x9a 0x9b 0x9c>;
		pinctrl-names = "default";
		power-domains = <0x8c 0x0a>;
		reg = <0x00 0xff380000 0x00 0x4000>;
		sd-uhs-sdr104;
		status = "okay";
		supports-sdio;
	};

	dwmmc@ff390000 {
		assigned-clock-parents = <0x02 0x53>;
		assigned-clocks = <0x02 0x39>;
		bus-width = <0x08>;
		cap-mmc-highspeed;
		clock-names = "biu", "ciu", "ciu-drv", "ciu-sample";
		clocks = <0x02 0x100 0x02 0x39 0x02 0x47 0x02 0x48>;
		compatible = "rockchip,px30-dw-mshc", "rockchip,rk3288-dw-mshc";
		disable-wp;
		fifo-depth = <0x100>;
		interrupts = <0x00 0x35 0x04>;
		max-frequency = <0x8f0d180>;
		mmc-hs200-1_8v;
		non-removable;
		num-slots = <0x01>;
		power-domains = <0x8c 0x0a>;
		reg = <0x00 0xff390000 0x00 0x4000>;
		status = "okay";
		supports-emmc;
	};

	ethernet@ff360000 {
		clock-names = "stmmaceth", "mac_clk_rx", "mac_clk_tx", "clk_mac_ref", "clk_mac_refout", "aclk_mac", "pclk_mac", "clk_mac_speed";
		clock_in_out = "output";
		clocks = <0x02 0x3e 0x02 0x3f 0x02 0x3f 0x02 0x40 0x02 0x41 0x02 0xb2 0x02 0x143 0x02 0x4c>;
		compatible = "rockchip,px30-gmac";
		interrupt-names = "macirq";
		interrupts = <0x00 0x2b 0x04>;
		phy-mode = "rmii";
		phy-supply = <0x94>;
		pinctrl-0 = <0x92 0x93>;
		pinctrl-names = "default";
		power-domains = <0x8c 0x09>;
		reg = <0x00 0xff360000 0x00 0x10000>;
		reset-names = "stmmaceth";
		resets = <0x02 0x5e>;
		rockchip,grf = <0x87>;
		snps,reset-active-low;
		snps,reset-delays-us = <0x00 0xc350 0xc350>;
		snps,reset-gpio = <0x69 0x0d 0x01>;
		status = "okay";
	};

	external-gmac-clock {
		#clock-cells = <0x00>;
		clock-frequency = <0x2faf080>;
		clock-output-names = "gmac_clkin";
		compatible = "fixed-clock";
	};

	fiq-debugger {
		compatible = "rockchip,fiq-debugger";
		interrupts = <0x00 0x7f 0x08>;
		pinctrl-0 = <0x4f>;
		pinctrl-names = "default";
		rockchip,baudrate = <0x16e360>;
		rockchip,irq-mode-enable = <0x00>;
		rockchip,serial-id = <0x02>;
		rockchip,wake-irq = <0x00>;
		status = "okay";
	};

	firmware {

		android {
			compatible = "android,firmware";

			fstab {
				compatible = "android,fstab";

				system {
					compatible = "android,system";
					dev = "/dev/block/by-name/system";
					fsmgr_flags = "wait";
					mnt_flags = "ro,barrier=1,inode_readahead_blks=8";
					type = "ext4";
				};

				vendor {
					compatible = "android,vendor";
					dev = "/dev/block/by-name/vendor";
					fsmgr_flags = "wait";
					mnt_flags = "ro,barrier=1,inode_readahead_blks=8";
					type = "ext4";
				};
			};
		};

		optee {
			compatible = "linaro,optee-tz";
			method = "smc";
		};
	};

	gpio_keys {
		#address-cells = <0x01>;
		#size-cells = <0x00>;
		autorepeat;
		compatible = "gpio-keys";
		status = "disabled";

		button@21 {
			gpios = <0x67 0x06 0x01>;
			label = "GPIO Key 1";
			linux,code = <0x3c>;
		};

		button@22 {
			gpios = <0x67 0x07 0x01>;
			label = "GPIO Key 2";
			linux,code = <0x3d>;
		};

		button@23 {
			gpios = <0x67 0x08 0x01>;
			label = "GPIO Key 3";
			linux,code = <0x3e>;
		};

		button@24 {
			gpios = <0x67 0x09 0x01>;
			label = "GPIO Key 4";
			linux,code = <0x3f>;
		};

		button@25 {
			gpios = <0x67 0x0a 0x01>;
			label = "GPIO Key 5";
			linux,code = <0x40>;
		};

		button@26 {
			gpios = <0x67 0x0b 0x01>;
			label = "GPIO Key 6";
			linux,code = <0x41>;
		};
	};

	gpu-opp-table {
		compatible = "operating-points-v2";
		phandle = <0x9e>;
		rockchip,evb-irdrop = <0x61a8>;
		rockchip,max-volt = <0x11edd8>;
		rockchip,pvtm-ch = <0x00 0x00>;
		rockchip,pvtm-voltage-sel = <0x00 0xc350 0x00 0xc351 0xd2f0 0x01 0xd2f1 0xea60 0x02 0xea61 0x1869f 0x03>;

		opp-200000000 {
			opp-hz = <0x00 0xbebc200>;
			opp-microvolt = <0xe7ef0>;
			opp-microvolt-L0 = <0xe7ef0>;
			opp-microvolt-L1 = <0xe7ef0>;
			opp-microvolt-L2 = <0xe7ef0>;
			opp-microvolt-L3 = <0xe7ef0>;
		};

		opp-300000000 {
			opp-hz = <0x00 0x11e1a300>;
			opp-microvolt = <0xee098>;
			opp-microvolt-L0 = <0xee098>;
			opp-microvolt-L1 = <0xe7ef0>;
			opp-microvolt-L2 = <0xe7ef0>;
			opp-microvolt-L3 = <0xe7ef0>;
		};

		opp-400000000 {
			opp-hz = <0x00 0x17d78400>;
			opp-microvolt = <0x100590>;
			opp-microvolt-L0 = <0x100590>;
			opp-microvolt-L1 = <0xfa3e8>;
			opp-microvolt-L2 = <0xee098>;
			opp-microvolt-L3 = <0xe7ef0>;
		};

		opp-480000000 {
			opp-hz = <0x00 0x1c9c3800>;
			opp-microvolt = <0x112a88>;
			opp-microvolt-L0 = <0x112a88>;
			opp-microvolt-L1 = <0x10c8e0>;
			opp-microvolt-L2 = <0x100590>;
			opp-microvolt-L3 = <0xf4240>;
		};
	};

	gpu@ff400000 {
		#cooling-cells = <0x02>;
		clock-names = "clk_mali";
		clocks = <0x02 0x49>;
		compatible = "arm,malit602", "arm,malit60x", "arm,malit6xx", "arm,mali-midgard";
		interrupt-names = "GPU", "MMU", "JOB";
		interrupts = <0x00 0x2d 0x04 0x00 0x2e 0x04 0x00 0x2f 0x04>;
		mali-supply = <0x0e>;
		operating-points-v2 = <0x9e>;
		phandle = <0x86>;
		power-domains = <0x8c 0x0e>;
		reg = <0x00 0xff400000 0x00 0x4000>;
		status = "okay";

		power_model {
			compatible = "arm,mali-simple-power-model";
			dynamic-coefficient = <0x2dd>;
			static-coefficient = <0x64578>;
			thermal-zone = "gpu-thermal";
			ts = <0x7d00 0x125c 0xffffffb0 0x02>;
		};
	};

	hevc_service@ff440000 {
		allocator = <0x01>;
		compatible = "rockchip,hevc_sub";
		dev_mode = <0x01>;
		interrupt-names = "irq_dec";
		interrupts = <0x00 0x31 0x04>;
		iommu_enabled = <0x01>;
		iommus = <0x9f>;
		phandle = <0xa2>;
		reg = <0x00 0xff440000 0x00 0x400>;
	};

	i2c@ff180000 {
		#address-cells = <0x01>;
		#size-cells = <0x00>;
		clock-names = "i2c", "pclk";
		clocks = <0x02 0x1d 0x02 0x14e>;
		compatible = "rockchip,rk3399-i2c";
		interrupts = <0x00 0x07 0x04>;
		pinctrl-0 = <0x59>;
		pinctrl-names = "default";
		reg = <0x00 0xff180000 0x00 0x1000>;
		status = "okay";

		pmic@20 {
			#clock-cells = <0x01>;
			clock-output-names = "rk808-clkout1", "rk808-clkout2";
			compatible = "rockchip,rk809";
			interrupt-parent = <0x5a>;
			interrupts = <0x07 0x08>;
			phandle = <0xcd>;
			pinctrl-0 = <0x5b>;
			pinctrl-1 = <0x5c 0x5d>;
			pinctrl-2 = <0x5e 0x5f>;
			pinctrl-3 = <0x60 0x61>;
			pinctrl-names = "default", "pmic-sleep", "pmic-power-off", "pmic-reset";
			pmic-reset-func = <0x01>;
			reg = <0x20>;
			rockchip,system-power-controller;
			vcc1-supply = <0x62>;
			vcc2-supply = <0x62>;
			vcc3-supply = <0x62>;
			vcc4-supply = <0x62>;
			vcc5-supply = <0x63>;
			vcc6-supply = <0x63>;
			vcc7-supply = <0x63>;
			vcc8-supply = <0x63>;
			vcc9-supply = <0x62>;
			wakeup-source;

			codec {
				#sound-dai-cells = <0x00>;
				adc-for-loopback;
				capture-volume = <0x14>;
				clock-names = "mclk";
				clocks = <0x02 0x15>;
				compatible = "rockchip,rk809-codec", "rockchip,rk817-codec";
				hp-volume = <0x14>;
				mic-in-differential;
				pdmdata-out-enable;
				phandle = <0xc9>;
				pinctrl-0 = <0x64>;
				pinctrl-names = "default";
				spk-volume = <0x08>;
				status = "okay";
			};

			pinctrl_rk8xx {
				#gpio-cells = <0x02>;
				gpio-controller;

				rk817_slppin_null {
					function = "pin_fun0";
					pins = "gpio_slp";
				};

				rk817_slppin_pwrdn {
					function = "pin_fun2";
					phandle = <0x5f>;
					pins = "gpio_slp";
				};

				rk817_slppin_rst {
					function = "pin_fun3";
					phandle = <0x61>;
					pins = "gpio_slp";
				};

				rk817_slppin_slp {
					function = "pin_fun1";
					phandle = <0x5d>;
					pins = "gpio_slp";
				};
			};

			pwrkey {
				status = "okay";
			};

			regulators {

				DCDC_REG1 {
					phandle = <0x0e>;
					regulator-always-on;
					regulator-boot-on;
					regulator-initial-mode = <0x02>;
					regulator-max-microvolt = <0x149970>;
					regulator-min-microvolt = <0xe7ef0>;
					regulator-name = "vdd_logic";
					regulator-ramp-delay = <0x1771>;

					regulator-state-mem {
						regulator-on-in-suspend;
						regulator-suspend-microvolt = <0xe7ef0>;
					};
				};

				DCDC_REG2 {
					phandle = <0x06>;
					regulator-always-on;
					regulator-boot-on;
					regulator-initial-mode = <0x02>;
					regulator-max-microvolt = <0x149970>;
					regulator-min-microvolt = <0xe7ef0>;
					regulator-name = "vdd_arm";
					regulator-ramp-delay = <0x1771>;

					regulator-state-mem {
						regulator-off-in-suspend;
						regulator-suspend-microvolt = <0xe7ef0>;
					};
				};

				DCDC_REG3 {
					regulator-always-on;
					regulator-boot-on;
					regulator-initial-mode = <0x02>;
					regulator-name = "vcc_ddr";

					regulator-state-mem {
						regulator-on-in-suspend;
					};
				};

				DCDC_REG4 {
					phandle = <0x4b>;
					regulator-always-on;
					regulator-boot-on;
					regulator-initial-mode = <0x02>;
					regulator-max-microvolt = <0x2dc6c0>;
					regulator-min-microvolt = <0x2dc6c0>;
					regulator-name = "vcc_3v0";

					regulator-state-mem {
						regulator-on-in-suspend;
						regulator-suspend-microvolt = <0x2dc6c0>;
					};
				};

				DCDC_REG5 {
					phandle = <0x63>;
					regulator-always-on;
					regulator-boot-on;
					regulator-max-microvolt = <0x325aa0>;
					regulator-min-microvolt = <0x325aa0>;
					regulator-name = "vcc3v3_sys";

					regulator-state-mem {
						regulator-on-in-suspend;
						regulator-suspend-microvolt = <0x325aa0>;
					};
				};

				LDO_REG1 {
					regulator-always-on;
					regulator-boot-on;
					regulator-max-microvolt = <0xf4240>;
					regulator-min-microvolt = <0xf4240>;
					regulator-name = "vcc_1v0";

					regulator-state-mem {
						regulator-on-in-suspend;
						regulator-suspend-microvolt = <0xf4240>;
					};
				};

				LDO_REG2 {
					phandle = <0x49>;
					regulator-always-on;
					regulator-boot-on;
					regulator-max-microvolt = <0x1b7740>;
					regulator-min-microvolt = <0x1b7740>;
					regulator-name = "vcc1v8_soc";

					regulator-state-mem {
						regulator-on-in-suspend;
						regulator-suspend-microvolt = <0x1b7740>;
					};
				};

				LDO_REG3 {
					regulator-always-on;
					regulator-boot-on;
					regulator-max-microvolt = <0xf4240>;
					regulator-min-microvolt = <0xf4240>;
					regulator-name = "vcc1v0_soc";

					regulator-state-mem {
						regulator-on-in-suspend;
						regulator-suspend-microvolt = <0xf4240>;
					};
				};

				LDO_REG4 {
					phandle = <0x2a>;
					regulator-always-on;
					regulator-boot-on;
					regulator-max-microvolt = <0x2dc6c0>;
					regulator-min-microvolt = <0x2dc6c0>;
					regulator-name = "vcc3v0_pmu";

					regulator-state-mem {
						regulator-on-in-suspend;
						regulator-suspend-microvolt = <0x2dc6c0>;
					};
				};

				LDO_REG5 {
					phandle = <0x4a>;
					regulator-always-on;
					regulator-boot-on;
					regulator-max-microvolt = <0x325aa0>;
					regulator-min-microvolt = <0x1b7740>;
					regulator-name = "vccio_sd";

					regulator-state-mem {
						regulator-on-in-suspend;
						regulator-suspend-microvolt = <0x325aa0>;
					};
				};

				LDO_REG6 {
					phandle = <0x99>;
					regulator-max-microvolt = <0x325aa0>;
					regulator-min-microvolt = <0x325aa0>;
					regulator-name = "vcc_sd";

					regulator-state-mem {
						regulator-on-in-suspend;
						regulator-suspend-microvolt = <0x325aa0>;
					};
				};

				LDO_REG7 {
					regulator-always-on;
					regulator-boot-on;
					regulator-max-microvolt = <0x325aa0>;
					regulator-min-microvolt = <0x325aa0>;
					regulator-name = "vcc2v8_dvp";

					regulator-state-mem {
						regulator-off-in-suspend;
						regulator-suspend-microvolt = <0x325aa0>;
					};
				};

				LDO_REG8 {
					regulator-always-on;
					regulator-boot-on;
					regulator-max-microvolt = <0x1b7740>;
					regulator-min-microvolt = <0x1b7740>;
					regulator-name = "vcc1v8_dvp";

					regulator-state-mem {
						regulator-on-in-suspend;
						regulator-suspend-microvolt = <0x1b7740>;
					};
				};

				LDO_REG9 {
					regulator-always-on;
					regulator-boot-on;
					regulator-max-microvolt = <0x2dc6c0>;
					regulator-min-microvolt = <0x2dc6c0>;
					regulator-name = "vdd1v5_dvp1";

					regulator-state-mem {
						regulator-off-in-suspend;
						regulator-suspend-microvolt = <0x2dc6c0>;
					};
				};

				SWITCH_REG1 {
					regulator-always-on;
					regulator-boot-on;
					regulator-name = "vcc5v0_host";
				};

				SWITCH_REG2 {
					phandle = <0x66>;
					regulator-boot-on;
					regulator-name = "vcc3v3_lcd";
				};
			};
		};
	};

	i2c@ff190000 {
		#address-cells = <0x01>;
		#size-cells = <0x00>;
		clock-names = "i2c", "pclk";
		clocks = <0x02 0x1e 0x02 0x14f>;
		compatible = "rockchip,rk3399-i2c";
		interrupts = <0x00 0x08 0x04>;
		pinctrl-0 = <0x65>;
		pinctrl-names = "default";
		reg = <0x00 0xff190000 0x00 0x1000>;
		status = "okay";

		cst226@1a {
			compatible = "HYN,CST226";
			irp-gpio = <0x5a 0x0d 0x08>;
			reg = <0x1a>;
			screen_max_x = <0x1e0>;
			screen_max_y = <0x1e0>;
			status = "okay";
			wake-gpio = <0x5a 0x0c 0x00>;
		};

		cst226se@5a {
			compatible = "HYN,CST226SE";
			irp-gpio = <0x5a 0x0d 0x08>;
			reg = <0x5a>;
			screen_max_x = <0x1e0>;
			screen_max_y = <0x1e0>;
			status = "okay";
			wake-gpio = <0x5a 0x0c 0x00>;
		};

		gsl1686@40 {
			compatible = "ilead,gsl2682";
			reg = <0x40>;
			reset-gpio = <0x5a 0x0c 0x00>;
			screen_max_x = <0x1e0>;
			screen_max_y = <0x1e0>;
			status = "disabled";
			touch-gpio = <0x5a 0x0d 0x08>;
		};

		gt1x@14 {
			compatible = "goodix,gt1x";
			goodix,irq-gpio = <0x5a 0x05 0x08>;
			goodix,rst-gpio = <0x5a 0x0c 0x00>;
			power-supply = <0x66>;
			reg = <0x14>;
			status = "disabled";
		};

		light@39 {
			compatible = "ls_apds9933";
			irq-gpio = <0x67 0x10 0x02>;
			irq_enable = <0x01>;
			reg = <0x39>;
			status = "disabled";
			type = <0x05>;
		};

		proximity@39 {
			compatible = "ps_apds9933";
			irq_enable = <0x00>;
			poll_delay_ms = <0xbb8>;
			reg = <0x39>;
			status = "disabled";
			type = <0x06>;
		};

		sensor@4c {
			compatible = "gs_mma7660";
			irq-gpio = <0x5a 0x0f 0x08>;
			irq_enable = <0x00>;
			layout = <0x02>;
			poll_delay_ms = <0x1e>;
			reg = <0x4c>;
			reprobe_en = <0x01>;
			status = "disabled";
			type = <0x02>;
		};

		sensor@f {
			compatible = "ak8963";
			irq_enable = <0x00>;
			layout = <0x01>;
			poll_delay_ms = <0x1e>;
			reg = <0x0f>;
			reprobe_en = <0x01>;
			status = "disabled";
			type = <0x03>;
		};
	};

	i2c@ff1a0000 {
		#address-cells = <0x01>;
		#size-cells = <0x00>;
		clock-frequency = <0x186a0>;
		clock-names = "i2c", "pclk";
		clocks = <0x02 0x1f 0x02 0x150>;
		compatible = "rockchip,rk3399-i2c";
		i2c-scl-falling-time-ns = <0x32>;
		i2c-scl-rising-time-ns = <0x12c>;
		interrupts = <0x00 0x09 0x04>;
		pinctrl-0 = <0x68>;
		pinctrl-names = "default";
		reg = <0x00 0xff1a0000 0x00 0x1000>;
		status = "okay";

		cht8305@40 {
			compatible = "px30-cht8305";
			reg = <0x40>;
			status = "disabled";
		};

		light@47 {
			compatible = "ls_stk3x3x";
			irq_enable = <0x00>;
			poll_delay_ms = <0x1e>;
			reg = <0x47>;
			status = "okay";
			type = <0x05>;
		};

		ov5695@36 {
			clock-names = "xvclk";
			clocks = <0x02 0x34>;
			compatible = "ovti,ov5695";
			pinctrl-0 = <0x6a>;
			pinctrl-names = "default";
			pwdn-gpios = <0x69 0x0e 0x00>;
			reg = <0x36>;
			status = "disabled";

			port {

				endpoint {
					data-lanes = <0x01 0x02>;
					phandle = <0x8e>;
					remote-endpoint = <0x6b>;
				};
			};
		};

		proximity@47 {
			compatible = "ps_stk3x3x";
			irq-gpio = <0x67 0x10 0x01>;
			irq_enable = <0x00>;
			poll_delay_ms = <0x1e>;
			reg = <0x47>;
			status = "okay";
			type = <0x06>;
		};

		sht21@40 {
			compatible = "px30-sht21";
			reg = <0x40>;
			status = "disabled";
		};

		smatek@3C {
			compatible = "smatek,tp";
			reg = <0x3c>;
			status = "okay";
		};
	};

	i2c@ff1b0000 {
		#address-cells = <0x01>;
		#size-cells = <0x00>;
		clock-names = "i2c", "pclk";
		clocks = <0x02 0x20 0x02 0x151>;
		compatible = "rockchip,rk3399-i2c";
		interrupts = <0x00 0x0a 0x04>;
		pinctrl-0 = <0x6c>;
		pinctrl-names = "default";
		reg = <0x00 0xff1b0000 0x00 0x1000>;
		status = "disabled";
	};

	i2s@ff060000 {
		clock-names = "mclk_tx", "mclk_rx", "hclk";
		clocks = <0x02 0x10 0x02 0x12 0x02 0x106>;
		compatible = "rockchip,px30-i2s-tdm", "rockchip,rk3308-i2s-tdm";
		dma-names = "tx", "rx";
		dmas = <0x2c 0x10 0x2c 0x11>;
		interrupts = <0x00 0x0c 0x04>;
		pinctrl-0 = <0x30 0x31 0x32 0x33 0x34 0x35 0x36 0x37 0x38 0x39 0x3a 0x3b>;
		pinctrl-names = "default";
		reg = <0x00 0xff060000 0x00 0x1000>;
		reset-names = "tx-m", "rx-m";
		resets = <0x02 0x84 0x02 0xbf>;
		rockchip,cru = <0x02>;
		status = "disabled";
	};

	i2s@ff070000 {
		#sound-dai-cells = <0x00>;
		clock-names = "i2s_clk", "i2s_hclk";
		clocks = <0x02 0x14 0x02 0x107>;
		compatible = "rockchip,px30-i2s", "rockchip,rk3066-i2s";
		dma-names = "tx", "rx";
		dmas = <0x2c 0x12 0x2c 0x13>;
		interrupts = <0x00 0x0d 0x04>;
		phandle = <0xc8>;
		pinctrl-0 = <0x3c 0x3d 0x3e>;
		pinctrl-names = "default";
		reg = <0x00 0xff070000 0x00 0x1000>;
		status = "okay";
	};

	i2s@ff080000 {
		clock-names = "i2s_clk", "i2s_hclk";
		clocks = <0x02 0x16 0x02 0x108>;
		compatible = "rockchip,px30-i2s", "rockchip,rk3066-i2s";
		dma-names = "tx", "rx";
		dmas = <0x2c 0x14 0x2c 0x15>;
		interrupts = <0x00 0x0e 0x04>;
		pinctrl-0 = <0x3f 0x40 0x41 0x42>;
		pinctrl-names = "default";
		reg = <0x00 0xff080000 0x00 0x1000>;
		status = "disabled";
	};

	interrupt-controller@ff131000 {
		#address-cells = <0x00>;
		#interrupt-cells = <0x03>;
		compatible = "arm,gic-400";
		interrupt-controller;
		interrupts = <0x01 0x09 0xf04>;
		phandle = <0x01>;
		reg = <0x00 0xff131000 0x00 0x1000 0x00 0xff132000 0x00 0x2000 0x00 0xff134000 0x00 0x2000 0x00 0xff136000 0x00 0x2000>;
	};

	iommu@ff440440 {
		#iommu-cells = <0x00>;
		clock-names = "aclk", "hclk";
		clocks = <0x02 0xaf 0x02 0xf4>;
		compatible = "rockchip,iommu";
		interrupt-names = "hevc_mmu";
		interrupts = <0x00 0x32 0x04>;
		phandle = <0x9f>;
		power-domains = <0x8c 0x0b>;
		reg = <0x00 0xff440440 0x00 0x40 0x00 0xff440480 0x00 0x40>;
	};

	iommu@ff442800 {
		#iommu-cells = <0x00>;
		clock-names = "aclk", "hclk";
		clocks = <0x02 0xaf 0x02 0xf4>;
		compatible = "rockchip,iommu";
		interrupt-names = "vpu_mmu";
		interrupts = <0x00 0x51 0x04>;
		phandle = <0xa0>;
		power-domains = <0x8c 0x0b>;
		reg = <0x00 0xff442800 0x00 0x100>;
	};

	iommu@ff460f00 {
		#iommu-cells = <0x00>;
		clock-names = "aclk", "hclk";
		clocks = <0x02 0xb5 0x02 0xfb>;
		compatible = "rockchip,iommu";
		interrupt-names = "vopb_mmu";
		interrupts = <0x00 0x4d 0x04>;
		phandle = <0xa7>;
		power-domains = <0x8c 0x0c>;
		reg = <0x00 0xff460f00 0x00 0x100>;
		status = "okay";
	};

	iommu@ff470f00 {
		#iommu-cells = <0x00>;
		clock-names = "aclk", "hclk";
		clocks = <0x02 0xb6 0x02 0xfc>;
		compatible = "rockchip,iommu";
		interrupt-names = "vopl_mmu";
		interrupts = <0x00 0x4f 0x04>;
		phandle = <0xab>;
		power-domains = <0x8c 0x0c>;
		reg = <0x00 0xff470f00 0x00 0x100>;
		status = "okay";
	};

	iommu@ff490800 {
		#iommu-cells = <0x00>;
		clock-names = "aclk", "hclk";
		clocks = <0x02 0xb3 0x02 0xf9>;
		compatible = "rockchip,iommu";
		interrupt-names = "vip_mmu";
		interrupts = <0x00 0x45 0x04>;
		phandle = <0xb0>;
		power-domains = <0x8c 0x0d>;
		reg = <0x00 0xff490800 0x00 0x100>;
		rk_iommu,disable_reset_quirk;
		status = "disabled";
	};

	iommu@ff4a8000 {
		#iommu-cells = <0x00>;
		clock-names = "aclk", "hclk";
		clocks = <0x02 0xb4 0x02 0xfa>;
		compatible = "rockchip,iommu";
		interrupt-names = "isp_mmu";
		interrupts = <0x00 0x46 0x04>;
		phandle = <0xb3>;
		power-domains = <0x8c 0x0d>;
		reg = <0x00 0xff4a8000 0x00 0x100>;
		rk_iommu,disable_reset_quirk;
		status = "disabled";
	};

	lvds@ff2e0000 {
		clock-names = "pclk_lvds", "pclk_lvds_ctl";
		clocks = <0x02 0x145 0x02 0x144>;
		compatible = "rockchip,px30-lvds";
		power-domains = <0x8c 0x0c>;
		reg = <0x00 0xff2e0000 0x00 0x10000 0x00 0xff450000 0x00 0x10000>;
		rockchip,grf = <0x87>;
		status = "disabled";

		ports {
			#address-cells = <0x01>;
			#size-cells = <0x00>;

			port@0 {
				#address-cells = <0x01>;
				#size-cells = <0x00>;
				reg = <0x00>;

				endpoint@0 {
					phandle = <0xa8>;
					reg = <0x00>;
					remote-endpoint = <0x13>;
				};

				endpoint@1 {
					phandle = <0xac>;
					reg = <0x01>;
					remote-endpoint = <0x8d>;
				};
			};
		};
	};

	mbi5041 {
		compatible = "px30-mbi";
		spi1_clk = <0x67 0x0f 0x00>;
		spi1_cs = <0x67 0x0d 0x01>;
		spi1_mosi = <0x67 0x0c 0x00>;
		status = "okay";
	};

	memory {
		device_type = "memory";
		reg = <0x00 0x200000 0x00 0x8200000 0x00 0xa200000 0x00 0x35e00000>;
	};

	mipi-dphy-rx0@ff2f0000 {
		clock-names = "dphy-ref";
		clocks = <0x02 0x146>;
		compatible = "rockchip,rk3326-mipi-dphy";
		power-domains = <0x8c 0x0d>;
		reg = <0x00 0xff2f0000 0x00 0x4000>;
		rockchip,grf = <0x87>;
		status = "disabled";

		ports {
			#address-cells = <0x01>;
			#size-cells = <0x00>;

			port@0 {
				#address-cells = <0x01>;
				#size-cells = <0x00>;
				reg = <0x00>;

				endpoint@1 {
					data-lanes = <0x01 0x02>;
					phandle = <0x6b>;
					reg = <0x01>;
					remote-endpoint = <0x8e>;
				};
			};

			port@1 {
				#address-cells = <0x01>;
				#size-cells = <0x00>;
				reg = <0x01>;

				endpoint@0 {
					phandle = <0xb5>;
					reg = <0x00>;
					remote-endpoint = <0x8f>;
				};
			};
		};
	};

	mipi-dphy@ff2e0000 {
		#clock-cells = <0x00>;
		#phy-cells = <0x00>;
		clock-names = "ref", "pclk";
		clock-output-names = "mipi_dphy_pll";
		clocks = <0x2b 0x0b 0x02 0x145>;
		compatible = "rockchip,px30-mipi-dphy";
		phandle = <0xa3>;
		power-domains = <0x8c 0x0c>;
		reg = <0x00 0xff2e0000 0x00 0x10000>;
		reset-names = "apb";
		resets = <0x02 0x3e>;
		rockchip,grf = <0x87>;
		status = "okay";
	};

	nandc@ff3b0000 {
		assigned-clock-parents = <0x02 0x4f>;
		assigned-clocks = <0x02 0x37>;
		clock-names = "clk_nandc", "hclk_nandc";
		clocks = <0x02 0x37 0x02 0xfe>;
		compatible = "rockchip,rk-nandc";
		interrupts = <0x00 0x39 0x04>;
		nandc_id = <0x00>;
		power-domains = <0x8c 0x0a>;
		reg = <0x00 0xff3b0000 0x00 0x4000>;
		status = "okay";
	};

	otp@ff290000 {
		#address-cells = <0x01>;
		#size-cells = <0x01>;
		clock-names = "clk_otp", "pclk_otp", "pclk_otp_phy";
		clocks = <0x02 0x2f 0x02 0x15a 0x02 0x161>;
		compatible = "rockchip,px30-otp";
		reg = <0x00 0xff290000 0x00 0x4000>;
		reset-names = "otp_phy";
		resets = <0x02 0xb4>;

		cpu-leakage@17 {
			phandle = <0x07>;
			reg = <0x17 0x01>;
		};

		id@7 {
			phandle = <0x0f>;
			reg = <0x07 0x10>;
		};

		performance@1e {
			bits = <0x04 0x03>;
			phandle = <0x08>;
			reg = <0x1e 0x01>;
		};
	};

	pdm@ff0a0000 {
		#sound-dai-cells = <0x00>;
		clock-names = "pdm_clk", "pdm_hclk";
		clocks = <0x02 0x0f 0x02 0x105>;
		compatible = "rockchip,px30-pdm", "rockchip,pdm";
		dma-names = "rx";
		dmas = <0x2c 0x18>;
		phandle = <0xca>;
		pinctrl-0 = <0x43 0x44 0x45 0x46 0x47 0x48>;
		pinctrl-names = "default";
		reg = <0x00 0xff0a0000 0x00 0x1000>;
		reset-names = "pdm-m";
		resets = <0x02 0x82>;
		status = "okay";
	};

	pinctrl {
		#address-cells = <0x02>;
		#size-cells = <0x02>;
		compatible = "rockchip,px30-pinctrl";
		ranges;
		rockchip,grf = <0x87>;
		rockchip,pmu = <0xb6>;

		cif-m0 {

			cif-clkout-m0 {
				phandle = <0x6a>;
				rockchip,pins = <0x02 0x0b 0x01 0xbb>;
			};

			d10-d11-m0 {
				phandle = <0xb1>;
				rockchip,pins = <0x02 0x0f 0x01 0xbb 0x02 0x10 0x01 0xbb>;
			};

			dvp-d0d1-m0 {
				phandle = <0xb2>;
				rockchip,pins = <0x02 0x0c 0x01 0xbb 0x02 0x0e 0x01 0xbb>;
			};

			dvp-d2d9-m0 {
				phandle = <0xaf>;
				rockchip,pins = <0x02 0x00 0x01 0xbb 0x02 0x01 0x01 0xbb 0x02 0x02 0x01 0xbb 0x02 0x03 0x01 0xbb 0x02 0x04 0x01 0xbb 0x02 0x05 0x01 0xbb 0x02 0x06 0x01 0xbb 0x02 0x07 0x01 0xbb 0x02 0x08 0x01 0xbb 0x02 0x09 0x01 0xbb 0x02 0x0a 0x01 0xbb 0x02 0x0b 0x01 0xbb>;
			};
		};

		cif-m1 {

			cif-clkout-m1 {
				rockchip,pins = <0x03 0x18 0x03 0xbb>;
			};

			d10-d11-m1 {
				rockchip,pins = <0x03 0x16 0x03 0xbb 0x03 0x17 0x03 0xbb>;
			};

			dvp-d0d1-m1 {
				rockchip,pins = <0x03 0x01 0x03 0xbb 0x03 0x02 0x03 0xbb>;
			};

			dvp-d2d9-m1 {
				rockchip,pins = <0x03 0x03 0x03 0xbb 0x03 0x05 0x03 0xbb 0x03 0x07 0x03 0xbb 0x03 0x08 0x03 0xbb 0x03 0x09 0x03 0xbb 0x03 0x0c 0x03 0xbb 0x03 0x0e 0x03 0xbb 0x03 0x0f 0x03 0xbb 0x03 0x19 0x03 0xbb 0x03 0x1a 0x03 0xbb 0x03 0x1b 0x03 0xbb 0x03 0x18 0x03 0xbb>;
			};
		};

		emmc {

			emmc-bus1 {
				rockchip,pins = <0x01 0x00 0x02 0xbe>;
			};

			emmc-bus4 {
				rockchip,pins = <0x01 0x00 0x02 0xbe 0x01 0x01 0x02 0xbe 0x01 0x02 0x02 0xbe 0x01 0x03 0x02 0xbe>;
			};

			emmc-bus8 {
				rockchip,pins = <0x01 0x00 0x02 0xbe 0x01 0x01 0x02 0xbe 0x01 0x02 0x02 0xbe 0x01 0x03 0x02 0xbe 0x01 0x04 0x02 0xbe 0x01 0x05 0x02 0xbe 0x01 0x06 0x02 0xbe 0x01 0x07 0x02 0xbe>;
			};

			emmc-clk {
				rockchip,pins = <0x01 0x09 0x02 0xc0>;
			};

			emmc-cmd {
				rockchip,pins = <0x01 0x0a 0x02 0xbe>;
			};

			emmc-pwren {
				rockchip,pins = <0x01 0x08 0x02 0xbb>;
			};

			emmc-rstnout {
				rockchip,pins = <0x01 0x0b 0x02 0xbb>;
			};
		};

		flash {

			flash-ale {
				rockchip,pins = <0x01 0x0b 0x01 0xbb>;
			};

			flash-bus8 {
				rockchip,pins = <0x01 0x00 0x01 0xc1 0x01 0x01 0x01 0xc1 0x01 0x02 0x01 0xc1 0x01 0x03 0x01 0xc1 0x01 0x04 0x01 0xc1 0x01 0x05 0x01 0xc1 0x01 0x06 0x01 0xc1 0x01 0x07 0x01 0xc1>;
			};

			flash-cle {
				rockchip,pins = <0x01 0x0c 0x01 0xbb>;
			};

			flash-cs0 {
				rockchip,pins = <0x01 0x08 0x01 0xbb>;
			};

			flash-csl {
				rockchip,pins = <0x01 0x0e 0x01 0xbb>;
			};

			flash-dqs {
				rockchip,pins = <0x01 0x0a 0x01 0xbb>;
			};

			flash-rdn {
				rockchip,pins = <0x01 0x0f 0x01 0xbb>;
			};

			flash-rdy {
				rockchip,pins = <0x01 0x09 0x01 0xbb>;
			};

			flash-wrn {
				rockchip,pins = <0x01 0x0d 0x01 0xbb>;
			};
		};

		gmac {

			mac-refclk {
				rockchip,pins = <0x02 0x0a 0x02 0xbb>;
			};

			mac-refclk-12ma {
				phandle = <0x93>;
				rockchip,pins = <0x02 0x0a 0x02 0xc2>;
			};

			rmii-pins {
				phandle = <0x92>;
				rockchip,pins = <0x02 0x00 0x02 0xc2 0x02 0x01 0x02 0xc2 0x02 0x02 0x02 0xc2 0x02 0x03 0x02 0xbb 0x02 0x04 0x02 0xbb 0x02 0x05 0x02 0xbb 0x02 0x06 0x02 0xbb 0x02 0x07 0x02 0xbb 0x02 0x09 0x02 0xbb>;
			};
		};

		gpio0@ff040000 {
			#gpio-cells = <0x02>;
			#interrupt-cells = <0x02>;
			clocks = <0x2b 0x14>;
			compatible = "rockchip,gpio-bank";
			gpio-controller;
			interrupt-controller;
			interrupts = <0x00 0x03 0x04>;
			phandle = <0x5a>;
			reg = <0x00 0xff040000 0x00 0x100>;
		};

		gpio1@ff250000 {
			#gpio-cells = <0x02>;
			#interrupt-cells = <0x02>;
			clocks = <0x02 0x15c>;
			compatible = "rockchip,gpio-bank";
			gpio-controller;
			interrupt-controller;
			interrupts = <0x00 0x04 0x04>;
			phandle = <0xce>;
			reg = <0x00 0xff250000 0x00 0x100>;
		};

		gpio2@ff260000 {
			#gpio-cells = <0x02>;
			#interrupt-cells = <0x02>;
			clocks = <0x02 0x15d>;
			compatible = "rockchip,gpio-bank";
			gpio-controller;
			interrupt-controller;
			interrupts = <0x00 0x05 0x04>;
			phandle = <0x69>;
			reg = <0x00 0xff260000 0x00 0x100>;
		};

		gpio3@ff270000 {
			#gpio-cells = <0x02>;
			#interrupt-cells = <0x02>;
			clocks = <0x02 0x15e>;
			compatible = "rockchip,gpio-bank";
			gpio-controller;
			interrupt-controller;
			interrupts = <0x00 0x06 0x04>;
			phandle = <0x67>;
			reg = <0x00 0xff270000 0x00 0x100>;
		};

		headphone {

			hp-det {
				phandle = <0xcb>;
				rockchip,pins = <0x02 0x08 0x00 0xc3>;
			};
		};

		i2c0 {

			i2c0-xfer {
				phandle = <0x59>;
				rockchip,pins = <0x00 0x08 0x01 0xba 0x00 0x09 0x01 0xba>;
			};
		};

		i2c1 {

			i2c1-xfer {
				phandle = <0x65>;
				rockchip,pins = <0x00 0x12 0x01 0xba 0x00 0x13 0x01 0xba>;
			};
		};

		i2c2 {

			i2c2-xfer {
				phandle = <0x68>;
				rockchip,pins = <0x02 0x0f 0x02 0xba 0x02 0x10 0x02 0xba>;
			};
		};

		i2c3 {

			i2c3-xfer {
				phandle = <0x6c>;
				rockchip,pins = <0x01 0x0c 0x04 0xba 0x01 0x0d 0x04 0xba>;
			};
		};

		i2s0 {

			i2s0-8ch-lrckrx {
				phandle = <0x33>;
				rockchip,pins = <0x03 0x0d 0x02 0xbb>;
			};

			i2s0-8ch-lrcktx {
				phandle = <0x32>;
				rockchip,pins = <0x03 0x12 0x02 0xbb>;
			};

			i2s0-8ch-mclk {
				rockchip,pins = <0x03 0x11 0x02 0xbb>;
			};

			i2s0-8ch-sclkrx {
				phandle = <0x31>;
				rockchip,pins = <0x03 0x0c 0x02 0xbb>;
			};

			i2s0-8ch-sclktx {
				phandle = <0x30>;
				rockchip,pins = <0x03 0x13 0x02 0xbb>;
			};

			i2s0-8ch-sdi0 {
				phandle = <0x34>;
				rockchip,pins = <0x03 0x15 0x02 0xbb>;
			};

			i2s0-8ch-sdi1 {
				phandle = <0x35>;
				rockchip,pins = <0x03 0x0b 0x02 0xbb>;
			};

			i2s0-8ch-sdi2 {
				phandle = <0x36>;
				rockchip,pins = <0x03 0x09 0x02 0xbb>;
			};

			i2s0-8ch-sdi3 {
				phandle = <0x37>;
				rockchip,pins = <0x03 0x08 0x02 0xbb>;
			};

			i2s0-8ch-sdo0 {
				phandle = <0x38>;
				rockchip,pins = <0x03 0x14 0x02 0xbb>;
			};

			i2s0-8ch-sdo1 {
				phandle = <0x39>;
				rockchip,pins = <0x03 0x10 0x02 0xbb>;
			};

			i2s0-8ch-sdo2 {
				phandle = <0x3a>;
				rockchip,pins = <0x03 0x0f 0x02 0xbb>;
			};

			i2s0-8ch-sdo3 {
				phandle = <0x3b>;
				rockchip,pins = <0x03 0x0e 0x02 0xbb>;
			};
		};

		i2s1 {

			i2s1-2ch-lrck {
				phandle = <0x3d>;
				rockchip,pins = <0x02 0x11 0x01 0xbb>;
			};

			i2s1-2ch-mclk {
				phandle = <0x64>;
				rockchip,pins = <0x02 0x13 0x01 0xbb>;
			};

			i2s1-2ch-sclk {
				phandle = <0x3c>;
				rockchip,pins = <0x02 0x12 0x01 0xbb>;
			};

			i2s1-2ch-sdi {
				rockchip,pins = <0x02 0x15 0x01 0xbb>;
			};

			i2s1-2ch-sdo {
				phandle = <0x3e>;
				rockchip,pins = <0x02 0x14 0x01 0xbb>;
			};
		};

		i2s2 {

			i2s2-2ch-lrck {
				phandle = <0x40>;
				rockchip,pins = <0x03 0x03 0x02 0xbb>;
			};

			i2s2-2ch-mclk {
				rockchip,pins = <0x03 0x01 0x02 0xbb>;
			};

			i2s2-2ch-sclk {
				phandle = <0x3f>;
				rockchip,pins = <0x03 0x02 0x02 0xbb>;
			};

			i2s2-2ch-sdi {
				phandle = <0x41>;
				rockchip,pins = <0x03 0x05 0x02 0xbb>;
			};

			i2s2-2ch-sdo {
				phandle = <0x42>;
				rockchip,pins = <0x03 0x07 0x02 0xbb>;
			};
		};

		isp {

			isp-prelight {
				rockchip,pins = <0x03 0x19 0x04 0xbb>;
			};
		};

		lcdc {

			lcdc-rgb-dclk-pin {
				rockchip,pins = <0x03 0x00 0x01 0xc2>;
			};

			lcdc-rgb-m0-den-pin {
				rockchip,pins = <0x03 0x03 0x01 0xc2>;
			};

			lcdc-rgb-m0-hsync-pin {
				rockchip,pins = <0x03 0x01 0x01 0xc2>;
			};

			lcdc-rgb-m0-vsync-pin {
				rockchip,pins = <0x03 0x02 0x01 0xc2>;
			};

			lcdc-rgb565-m0-data-pins {
				rockchip,pins = <0x03 0x07 0x01 0xc0 0x03 0x06 0x01 0xc0 0x03 0x05 0x01 0xc0 0x03 0x04 0x01 0xc0 0x03 0x0b 0x01 0xc0 0x03 0x0a 0x01 0xc0 0x03 0x09 0x01 0xc0 0x03 0x08 0x01 0xc0 0x03 0x0f 0x01 0xc0 0x03 0x0e 0x01 0xc0 0x03 0x0d 0x01 0xc0 0x03 0x0c 0x01 0xc0 0x03 0x13 0x01 0xc0 0x03 0x12 0x01 0xc0 0x03 0x11 0x01 0xc0 0x03 0x10 0x01 0xc0>;
			};

			lcdc-rgb565-m1-data-pins {
				rockchip,pins = <0x03 0x06 0x01 0xc0 0x03 0x04 0x01 0xc0 0x03 0x0b 0x01 0xc0 0x03 0x0a 0x01 0xc0 0x03 0x0d 0x01 0xc0 0x03 0x13 0x01 0xc0 0x03 0x12 0x01 0xc0 0x03 0x11 0x01 0xc0 0x03 0x10 0x01 0xc0>;
			};

			lcdc-rgb666-m0-data-pins {
				rockchip,pins = <0x03 0x07 0x01 0xc0 0x03 0x06 0x01 0xc0 0x03 0x05 0x01 0xc0 0x03 0x04 0x01 0xc0 0x03 0x0b 0x01 0xc0 0x03 0x0a 0x01 0xc0 0x03 0x09 0x01 0xc0 0x03 0x08 0x01 0xc0 0x03 0x0f 0x01 0xc0 0x03 0x0e 0x01 0xc0 0x03 0x0d 0x01 0xc0 0x03 0x0c 0x01 0xc0 0x03 0x13 0x01 0xc0 0x03 0x12 0x01 0xc0 0x03 0x11 0x01 0xc0 0x03 0x10 0x01 0xc0 0x03 0x15 0x01 0xc0 0x03 0x14 0x01 0xc0>;
			};

			lcdc-rgb666-m1-data-pins {
				rockchip,pins = <0x03 0x06 0x01 0xc0 0x03 0x04 0x01 0xc0 0x03 0x0b 0x01 0xc0 0x03 0x0a 0x01 0xc0 0x03 0x0d 0x01 0xc0 0x03 0x13 0x01 0xc0 0x03 0x12 0x01 0xc0 0x03 0x11 0x01 0xc0 0x03 0x10 0x01 0xc0 0x03 0x15 0x01 0xc0 0x03 0x14 0x01 0xc0>;
			};

			lcdc-rgb888-m0-data-pins {
				rockchip,pins = <0x03 0x07 0x01 0xc0 0x03 0x06 0x01 0xc0 0x03 0x05 0x01 0xc0 0x03 0x04 0x01 0xc0 0x03 0x0b 0x01 0xc0 0x03 0x0a 0x01 0xc0 0x03 0x09 0x01 0xc0 0x03 0x08 0x01 0xc0 0x03 0x0f 0x01 0xc0 0x03 0x0e 0x01 0xc0 0x03 0x0d 0x01 0xc0 0x03 0x0c 0x01 0xc0 0x03 0x13 0x01 0xc0 0x03 0x12 0x01 0xc0 0x03 0x11 0x01 0xc0 0x03 0x10 0x01 0xc0 0x03 0x17 0x01 0xc0 0x03 0x16 0x01 0xc0 0x03 0x15 0x01 0xc0 0x03 0x14 0x01 0xc0 0x03 0x1b 0x01 0xc0 0x03 0x1a 0x01 0xc0 0x03 0x19 0x01 0xc0 0x03 0x18 0x01 0xc0>;
			};

			lcdc-rgb888-m1-data-pins {
				rockchip,pins = <0x03 0x06 0x01 0xc0 0x03 0x04 0x01 0xc0 0x03 0x0b 0x01 0xc0 0x03 0x0a 0x01 0xc0 0x03 0x0d 0x01 0xc0 0x03 0x13 0x01 0xc0 0x03 0x12 0x01 0xc0 0x03 0x11 0x01 0xc0 0x03 0x10 0x01 0xc0 0x03 0x17 0x01 0xc0 0x03 0x16 0x01 0xc0 0x03 0x15 0x01 0xc0 0x03 0x14 0x01 0xc0 0x03 0x1b 0x01 0xc0 0x03 0x1a 0x01 0xc0 0x03 0x19 0x01 0xc0 0x03 0x18 0x01 0xc0>;
			};
		};

		pcfg-input {
			input-enable;
		};

		pcfg-input-high {
			bias-pull-up;
			input-enable;
			phandle = <0xbf>;
		};

		pcfg-output-high {
			output-high;
		};

		pcfg-output-low {
			output-low;
			phandle = <0xc4>;
		};

		pcfg-pull-down {
			bias-pull-down;
			phandle = <0xc3>;
		};

		pcfg-pull-down-4ma {
			bias-pull-down;
			drive-strength = <0x04>;
		};

		pcfg-pull-none {
			bias-disable;
			phandle = <0xbb>;
		};

		pcfg-pull-none-12ma {
			bias-disable;
			drive-strength = <0x0c>;
			phandle = <0xc2>;
		};

		pcfg-pull-none-2ma {
			bias-disable;
			drive-strength = <0x02>;
		};

		pcfg-pull-none-4ma {
			bias-disable;
			drive-strength = <0x04>;
		};

		pcfg-pull-none-8ma {
			bias-disable;
			drive-strength = <0x08>;
			phandle = <0xc0>;
		};

		pcfg-pull-none-smt {
			bias-disable;
			input-schmitt-enable;
			phandle = <0xba>;
		};

		pcfg-pull-up {
			bias-pull-up;
			phandle = <0xbc>;
		};

		pcfg-pull-up-12ma {
			bias-pull-up;
			drive-strength = <0x0c>;
			phandle = <0xc1>;
		};

		pcfg-pull-up-2ma {
			bias-pull-up;
			drive-strength = <0x02>;
		};

		pcfg-pull-up-4ma {
			bias-pull-up;
			drive-strength = <0x04>;
			phandle = <0xbd>;
		};

		pcfg-pull-up-8ma {
			bias-pull-up;
			drive-strength = <0x08>;
			phandle = <0xbe>;
		};

		pdm {

			pdm-clk0m0 {
				rockchip,pins = <0x03 0x16 0x02 0xbb>;
			};

			pdm-clk0m0-sleep {
				rockchip,pins = <0x03 0x16 0x00 0xbf>;
			};

			pdm-clk0m1 {
				phandle = <0x43>;
				rockchip,pins = <0x02 0x16 0x01 0xbb>;
			};

			pdm-clk0m1-sleep {
				rockchip,pins = <0x02 0x16 0x00 0xbf>;
			};

			pdm-clk1 {
				phandle = <0x44>;
				rockchip,pins = <0x03 0x17 0x02 0xbb>;
			};

			pdm-clk1-sleep {
				rockchip,pins = <0x03 0x17 0x00 0xbf>;
			};

			pdm-sdi0m0 {
				rockchip,pins = <0x03 0x1b 0x02 0xbb>;
			};

			pdm-sdi0m0-sleep {
				rockchip,pins = <0x03 0x1b 0x00 0xbf>;
			};

			pdm-sdi0m1 {
				phandle = <0x45>;
				rockchip,pins = <0x02 0x15 0x02 0xbb>;
			};

			pdm-sdi0m1-sleep {
				rockchip,pins = <0x02 0x15 0x00 0xbf>;
			};

			pdm-sdi1 {
				phandle = <0x46>;
				rockchip,pins = <0x03 0x18 0x02 0xbb>;
			};

			pdm-sdi1-sleep {
				rockchip,pins = <0x03 0x18 0x00 0xbf>;
			};

			pdm-sdi2 {
				phandle = <0x47>;
				rockchip,pins = <0x03 0x19 0x02 0xbb>;
			};

			pdm-sdi2-sleep {
				rockchip,pins = <0x03 0x19 0x00 0xbf>;
			};

			pdm-sdi3 {
				phandle = <0x48>;
				rockchip,pins = <0x03 0x1a 0x02 0xbb>;
			};

			pdm-sdi3-sleep {
				rockchip,pins = <0x03 0x1a 0x00 0xbf>;
			};
		};

		pmic {

			pmic_int {
				phandle = <0x5b>;
				rockchip,pins = <0x00 0x07 0x00 0xbc>;
			};

			soc_slppin_gpio {
				phandle = <0x5e>;
				rockchip,pins = <0x00 0x04 0x00 0xc4>;
			};

			soc_slppin_rst {
				phandle = <0x60>;
				rockchip,pins = <0x00 0x04 0x02 0xbb>;
			};

			soc_slppin_slp {
				phandle = <0x5c>;
				rockchip,pins = <0x00 0x04 0x01 0xbb>;
			};
		};

		pwm0 {

			pwm0-pin {
				phandle = <0x7c>;
				rockchip,pins = <0x00 0x0f 0x01 0xbb>;
			};
		};

		pwm1 {

			pwm1-pin {
				phandle = <0x7d>;
				rockchip,pins = <0x00 0x10 0x01 0xbb>;
			};
		};

		pwm2 {

			pwm2-pin {
				phandle = <0x7e>;
				rockchip,pins = <0x02 0x0d 0x01 0xbb>;
			};
		};

		pwm3 {

			pwm3-pin {
				phandle = <0x7f>;
				rockchip,pins = <0x00 0x11 0x01 0xbb>;
			};
		};

		pwm4 {

			pwm4-pin {
				phandle = <0x80>;
				rockchip,pins = <0x03 0x12 0x03 0xbb>;
			};
		};

		pwm5 {

			pwm5-pin {
				phandle = <0x81>;
				rockchip,pins = <0x03 0x13 0x03 0xbb>;
			};
		};

		pwm6 {

			pwm6-pin {
				phandle = <0x82>;
				rockchip,pins = <0x03 0x14 0x03 0xbb>;
			};
		};

		pwm7 {

			pwm7-pin {
				phandle = <0x83>;
				rockchip,pins = <0x03 0x15 0x03 0xbb>;
			};
		};

		sdio {

			sdio-bus4 {
				phandle = <0x9a>;
				rockchip,pins = <0x01 0x16 0x01 0xbc 0x01 0x17 0x01 0xbc 0x01 0x18 0x01 0xbc 0x01 0x19 0x01 0xbc>;
			};

			sdio-clk {
				phandle = <0x9c>;
				rockchip,pins = <0x01 0x15 0x01 0xbb>;
			};

			sdio-cmd {
				phandle = <0x9b>;
				rockchip,pins = <0x01 0x14 0x01 0xbc>;
			};

			sdio-gpio {
				rockchip,pins = <0x01 0x16 0x00 0xbc 0x01 0x17 0x00 0xbc 0x01 0x18 0x00 0xbc 0x01 0x19 0x00 0xbc 0x01 0x14 0x00 0xbc 0x01 0x15 0x00 0xbc>;
			};
		};

		sdio-pwrseq {

			wifi-enable-h {
				phandle = <0xcc>;
				rockchip,pins = <0x00 0x02 0x00 0xbb>;
			};
		};

		sdmmc {

			sdmmc-bus1 {
				rockchip,pins = <0x01 0x1a 0x01 0xbe>;
			};

			sdmmc-bus4 {
				phandle = <0x98>;
				rockchip,pins = <0x01 0x1a 0x01 0xbe 0x01 0x1b 0x01 0xbe 0x01 0x1c 0x01 0xbe 0x01 0x1d 0x01 0xbe>;
			};

			sdmmc-clk {
				phandle = <0x95>;
				rockchip,pins = <0x01 0x1e 0x01 0xc0>;
			};

			sdmmc-cmd {
				phandle = <0x96>;
				rockchip,pins = <0x01 0x1f 0x01 0xbe>;
			};

			sdmmc-det {
				phandle = <0x97>;
				rockchip,pins = <0x00 0x03 0x01 0xbe>;
			};

			sdmmc-gpio {
				rockchip,pins = <0x01 0x1a 0x00 0xbd 0x01 0x1b 0x00 0xbd 0x01 0x1c 0x00 0xbd 0x01 0x1d 0x00 0xbd 0x01 0x1e 0x00 0xbd 0x01 0x1f 0x00 0xbd>;
			};
		};

		spi0 {

			spi0-clk {
				phandle = <0x6d>;
				rockchip,pins = <0x01 0x0f 0x03 0xbd>;
			};

			spi0-clk-hs {
				phandle = <0x71>;
				rockchip,pins = <0x01 0x0f 0x03 0xbe>;
			};

			spi0-csn {
				phandle = <0x6e>;
				rockchip,pins = <0x01 0x0e 0x03 0xbd>;
			};

			spi0-miso {
				phandle = <0x6f>;
				rockchip,pins = <0x01 0x0d 0x03 0xbd>;
			};

			spi0-miso-hs {
				phandle = <0x72>;
				rockchip,pins = <0x01 0x0d 0x03 0xbe>;
			};

			spi0-mosi {
				phandle = <0x70>;
				rockchip,pins = <0x01 0x0c 0x03 0xbd>;
			};

			spi0-mosi-hs {
				phandle = <0x73>;
				rockchip,pins = <0x01 0x0c 0x03 0xbe>;
			};
		};

		spi1 {

			spi1-clk {
				phandle = <0x74>;
				rockchip,pins = <0x03 0x0f 0x04 0xbd>;
			};

			spi1-clk-hs {
				phandle = <0x79>;
				rockchip,pins = <0x03 0x0f 0x04 0xbe>;
			};

			spi1-csn0 {
				phandle = <0x75>;
				rockchip,pins = <0x03 0x09 0x04 0xbd>;
			};

			spi1-csn1 {
				phandle = <0x76>;
				rockchip,pins = <0x03 0x0a 0x02 0xbd>;
			};

			spi1-miso {
				phandle = <0x77>;
				rockchip,pins = <0x03 0x0e 0x04 0xbd>;
			};

			spi1-miso-hs {
				phandle = <0x7a>;
				rockchip,pins = <0x03 0x0e 0x04 0xbe>;
			};

			spi1-mosi {
				phandle = <0x78>;
				rockchip,pins = <0x03 0x0c 0x04 0xbd>;
			};

			spi1-mosi-hs {
				phandle = <0x7b>;
				rockchip,pins = <0x03 0x0c 0x04 0xbe>;
			};
		};

		tsadc {

			tsadc-otp-gpio {
				phandle = <0x88>;
				rockchip,pins = <0x00 0x06 0x00 0xbb>;
			};

			tsadc-otp-out {
				phandle = <0x89>;
				rockchip,pins = <0x00 0x06 0x01 0xbb>;
			};
		};

		uart0 {

			uart0-cts {
				phandle = <0x2e>;
				rockchip,pins = <0x00 0x0c 0x01 0xbb>;
			};

			uart0-rts {
				phandle = <0x2f>;
				rockchip,pins = <0x00 0x0d 0x01 0xbb>;
			};

			uart0-rts-gpio {
				rockchip,pins = <0x00 0x0d 0x00 0xbb>;
			};

			uart0-xfer {
				phandle = <0x2d>;
				rockchip,pins = <0x00 0x0a 0x01 0xbc 0x00 0x0b 0x01 0xbc>;
			};
		};

		uart1 {

			uart1-cts {
				phandle = <0x4e>;
				rockchip,pins = <0x01 0x12 0x01 0xbb>;
			};

			uart1-rts {
				phandle = <0xcf>;
				rockchip,pins = <0x01 0x13 0x01 0xbb>;
			};

			uart1-rts-gpio {
				phandle = <0xd0>;
				rockchip,pins = <0x01 0x13 0x00 0xbb>;
			};

			uart1-xfer {
				phandle = <0x4d>;
				rockchip,pins = <0x01 0x11 0x01 0xbc 0x01 0x10 0x01 0xbc>;
			};
		};

		uart2-m0 {

			uart2m0-xfer {
				phandle = <0x4f>;
				rockchip,pins = <0x01 0x1a 0x02 0xbc 0x01 0x1b 0x02 0xbc>;
			};
		};

		uart2-m1 {

			uart2m1-xfer {
				rockchip,pins = <0x02 0x0c 0x02 0xbc 0x02 0x0e 0x02 0xbc>;
			};
		};

		uart3-m0 {

			uart3m0-cts {
				rockchip,pins = <0x00 0x12 0x02 0xbb>;
			};

			uart3m0-rts {
				rockchip,pins = <0x00 0x13 0x02 0xbb>;
			};

			uart3m0-rts-gpio {
				rockchip,pins = <0x00 0x13 0x00 0xbb>;
			};

			uart3m0-xfer {
				rockchip,pins = <0x00 0x10 0x02 0xbc 0x00 0x11 0x02 0xbc>;
			};
		};

		uart3-m1 {

			uart3m1-cts {
				phandle = <0x51>;
				rockchip,pins = <0x01 0x0c 0x02 0xbb>;
			};

			uart3m1-rts {
				phandle = <0x52>;
				rockchip,pins = <0x01 0x0d 0x02 0xbb>;
			};

			uart3m1-rts-gpio {
				rockchip,pins = <0x01 0x0d 0x00 0xbb>;
			};

			uart3m1-xfer {
				phandle = <0x50>;
				rockchip,pins = <0x01 0x0e 0x02 0xbc 0x01 0x0f 0x02 0xbc>;
			};
		};

		uart4 {

			uart4-cts {
				phandle = <0x54>;
				rockchip,pins = <0x01 0x1e 0x02 0xbb>;
			};

			uart4-rts {
				phandle = <0x55>;
				rockchip,pins = <0x01 0x1f 0x02 0xbb>;
			};

			uart4-xfer {
				phandle = <0x53>;
				rockchip,pins = <0x01 0x1c 0x02 0xbc 0x01 0x1d 0x02 0xbc>;
			};
		};

		uart5 {

			uart5-cts {
				phandle = <0x57>;
				rockchip,pins = <0x03 0x03 0x04 0xbb>;
			};

			uart5-rts {
				phandle = <0x58>;
				rockchip,pins = <0x03 0x05 0x04 0xbb>;
			};

			uart5-xfer {
				phandle = <0x56>;
				rockchip,pins = <0x03 0x02 0x04 0xbc 0x03 0x01 0x04 0xbc>;
			};
		};
	};

	pmu-clock-controller@ff2bc000 {
		#clock-cells = <0x01>;
		#reset-cells = <0x01>;
		assigned-clock-rates = <0x47868c00 0x5f5e100 0x18cba80 0x23c34600 0xbebc200 0xbebc200 0x8f0d180 0x8f0d180 0x5f5e100 0xbebc200 0x3a980000 0x5dc0000>;
		assigned-clocks = <0x2b 0x01 0x2b 0x08 0x2b 0x05 0x02 0x07 0x02 0xab 0x02 0xb0 0x02 0xf0 0x02 0xf5 0x02 0x140 0x02 0x49 0x02 0x04 0x02 0x0f>;
		compatible = "rockchip,px30-pmucru";
		phandle = <0x2b>;
		reg = <0x00 0xff2bc000 0x00 0x1000>;
		rockchip,grf = <0x87>;
	};

	power-management@ff000000 {
		compatible = "rockchip,px30-pmu", "syscon", "simple-mfd";
		reg = <0x00 0xff000000 0x00 0x1000>;

		power-controller {
			#address-cells = <0x01>;
			#power-domain-cells = <0x01>;
			#size-cells = <0x00>;
			compatible = "rockchip,px30-power-controller";
			phandle = <0x8c>;

			pd_gmac@9 {
				clocks = <0x02 0xb2 0x02 0x143 0x02 0x40 0x02 0x3f>;
				pm_qos = <0x19>;
				reg = <0x09>;
			};

			pd_gpu@14 {
				clocks = <0x02 0x49>;
				pm_qos = <0x29>;
				reg = <0x0e>;
			};

			pd_mmc_nand@10 {
				clocks = <0x02 0xfe 0x02 0x100 0x02 0xff 0x02 0x101 0x02 0x39 0x02 0x37 0x02 0x38 0x02 0x3a>;
				pm_qos = <0x1a 0x1b 0x1c 0x1d>;
				reg = <0x0a>;
			};

			pd_sdcard@7 {
				clocks = <0x02 0xf7 0x02 0x3b>;
				pm_qos = <0x18>;
				reg = <0x07>;
			};

			pd_usb@5 {
				clocks = <0x02 0x103 0x02 0x102 0x02 0x3c>;
				pm_qos = <0x16 0x17>;
				reg = <0x05>;
			};

			pd_vi@13 {
				clocks = <0x02 0xb3 0x02 0xb4 0x02 0xf9 0x02 0xfa 0x02 0x33>;
				pm_qos = <0x24 0x25 0x26 0x27 0x28>;
				reg = <0x0d>;
			};

			pd_vo@12 {
				clocks = <0x02 0xb7 0x02 0xb5 0x02 0xb6 0x02 0x96 0x02 0x97 0x02 0xfd 0x02 0xfb 0x02 0xfc 0x02 0x144 0x02 0x35 0x02 0x36>;
				pm_qos = <0x20 0x21 0x22 0x23>;
				reg = <0x0c>;
			};

			pd_vpu@11 {
				clocks = <0x02 0xaf 0x02 0xf4 0x02 0x4b>;
				pm_qos = <0x1e 0x1f>;
				reg = <0x0b>;
			};
		};
	};

	psci {
		compatible = "arm,psci-1.0";
		method = "smc";
	};

	pwm@ff200000 {
		#pwm-cells = <0x03>;
		clock-names = "pwm", "pclk";
		clocks = <0x02 0x22 0x02 0x153>;
		compatible = "rockchip,px30-pwm", "rockchip,rk3328-pwm";
		pinctrl-0 = <0x7c>;
		pinctrl-names = "active";
		reg = <0x00 0xff200000 0x00 0x10>;
		status = "okay";
	};

	pwm@ff200010 {
		#pwm-cells = <0x03>;
		clock-names = "pwm", "pclk";
		clocks = <0x02 0x22 0x02 0x153>;
		compatible = "rockchip,px30-pwm", "rockchip,rk3328-pwm";
		phandle = <0xc7>;
		pinctrl-0 = <0x7d>;
		pinctrl-names = "active";
		reg = <0x00 0xff200010 0x00 0x10>;
		status = "okay";
	};

	pwm@ff200020 {
		#pwm-cells = <0x03>;
		clock-names = "pwm", "pclk";
		clocks = <0x02 0x22 0x02 0x153>;
		compatible = "rockchip,px30-pwm", "rockchip,rk3328-pwm";
		pinctrl-0 = <0x7e>;
		pinctrl-names = "active";
		reg = <0x00 0xff200020 0x00 0x10>;
		status = "disabled";
	};

	pwm@ff200030 {
		#pwm-cells = <0x03>;
		clock-names = "pwm", "pclk";
		clocks = <0x02 0x22 0x02 0x153>;
		compatible = "rockchip,px30-pwm", "rockchip,rk3328-pwm";
		pinctrl-0 = <0x7f>;
		pinctrl-names = "active";
		reg = <0x00 0xff200030 0x00 0x10>;
		status = "disabled";
	};

	pwm@ff208000 {
		#pwm-cells = <0x03>;
		clock-names = "pwm", "pclk";
		clocks = <0x02 0x23 0x02 0x154>;
		compatible = "rockchip,px30-pwm", "rockchip,rk3328-pwm";
		pinctrl-0 = <0x80>;
		pinctrl-names = "active";
		reg = <0x00 0xff208000 0x00 0x10>;
		status = "disabled";
	};

	pwm@ff208010 {
		#pwm-cells = <0x03>;
		clock-names = "pwm", "pclk";
		clocks = <0x02 0x23 0x02 0x154>;
		compatible = "rockchip,px30-pwm", "rockchip,rk3328-pwm";
		pinctrl-0 = <0x81>;
		pinctrl-names = "active";
		reg = <0x00 0xff208010 0x00 0x10>;
		status = "disabled";
	};

	pwm@ff208020 {
		#pwm-cells = <0x03>;
		clock-names = "pwm", "pclk";
		clocks = <0x02 0x23 0x02 0x154>;
		compatible = "rockchip,px30-pwm", "rockchip,rk3328-pwm";
		pinctrl-0 = <0x82>;
		pinctrl-names = "active";
		reg = <0x00 0xff208020 0x00 0x10>;
		status = "disabled";
	};

	pwm@ff208030 {
		#pwm-cells = <0x03>;
		clock-names = "pwm", "pclk";
		clocks = <0x02 0x23 0x02 0x154>;
		compatible = "rockchip,px30-pwm", "rockchip,rk3328-pwm";
		pinctrl-0 = <0x83>;
		pinctrl-names = "active";
		reg = <0x00 0xff208030 0x00 0x10>;
		status = "disabled";
	};

	qos@ff518000 {
		compatible = "syscon";
		phandle = <0x19>;
		reg = <0x00 0xff518000 0x00 0x20>;
	};

	qos@ff520000 {
		compatible = "syscon";
		phandle = <0x29>;
		reg = <0x00 0xff520000 0x00 0x20>;
	};

	qos@ff52c000 {
		compatible = "syscon";
		phandle = <0x18>;
		reg = <0x00 0xff52c000 0x00 0x20>;
	};

	qos@ff538000 {
		compatible = "syscon";
		phandle = <0x1a>;
		reg = <0x00 0xff538000 0x00 0x20>;
	};

	qos@ff538080 {
		compatible = "syscon";
		phandle = <0x1b>;
		reg = <0x00 0xff538080 0x00 0x20>;
	};

	qos@ff538100 {
		compatible = "syscon";
		phandle = <0x1c>;
		reg = <0x00 0xff538100 0x00 0x20>;
	};

	qos@ff538180 {
		compatible = "syscon";
		phandle = <0x1d>;
		reg = <0x00 0xff538180 0x00 0x20>;
	};

	qos@ff540000 {
		compatible = "syscon";
		phandle = <0x16>;
		reg = <0x00 0xff540000 0x00 0x20>;
	};

	qos@ff540080 {
		compatible = "syscon";
		phandle = <0x17>;
		reg = <0x00 0xff540080 0x00 0x20>;
	};

	qos@ff548000 {
		compatible = "syscon";
		phandle = <0x24>;
		reg = <0x00 0xff548000 0x00 0x20>;
	};

	qos@ff548080 {
		compatible = "syscon";
		phandle = <0x25>;
		reg = <0x00 0xff548080 0x00 0x20>;
	};

	qos@ff548100 {
		compatible = "syscon";
		phandle = <0x26>;
		reg = <0x00 0xff548100 0x00 0x20>;
	};

	qos@ff548180 {
		compatible = "syscon";
		phandle = <0x27>;
		reg = <0x00 0xff548180 0x00 0x20>;
	};

	qos@ff548200 {
		compatible = "syscon";
		phandle = <0x28>;
		reg = <0x00 0xff548200 0x00 0x20>;
	};

	qos@ff550000 {
		compatible = "syscon";
		phandle = <0x20>;
		reg = <0x00 0xff550000 0x00 0x20>;
	};

	qos@ff550080 {
		compatible = "syscon";
		phandle = <0x21>;
		reg = <0x00 0xff550080 0x00 0x20>;
	};

	qos@ff550100 {
		compatible = "syscon";
		phandle = <0x22>;
		reg = <0x00 0xff550100 0x00 0x20>;
	};

	qos@ff550180 {
		compatible = "syscon";
		phandle = <0x23>;
		reg = <0x00 0xff550180 0x00 0x20>;
	};

	qos@ff558000 {
		compatible = "syscon";
		phandle = <0x1e>;
		reg = <0x00 0xff558000 0x00 0x20>;
	};

	qos@ff558080 {
		compatible = "syscon";
		phandle = <0x1f>;
		reg = <0x00 0xff558080 0x00 0x20>;
	};

	ramoops {
		compatible = "ramoops";
		console-size = <0x00 0x80000>;
		ftrace-size = <0x00 0x00>;
		memory-region = <0xc5>;
		pmsg-size = <0x00 0x50000>;
		record-size = <0x00 0x20000>;
	};

	ramoops_mem@110000 {
		phandle = <0xc5>;
		reg = <0x00 0x110000 0x00 0xf0000>;
		reg-names = "ramoops_mem";
	};

	reserved-memory {
		#address-cells = <0x02>;
		#size-cells = <0x02>;
		ranges;

		drm-logo@00000000 {
			compatible = "rockchip,drm-logo";
			phandle = <0x12>;
			reg = <0x00 0x3df00000 0x00 0xa9800>;
		};
	};

	rk809-sound {
		compatible = "simple-audio-card";
		simple-audio-card,mclk-fs = <0x100>;
		simple-audio-card,name = "rockchip,rk809-codec";
		simple-audio-card,routing = "Mic Jack", "MICBIAS1", "IN1P", "Mic Jack", "Headphone Jack", "HPOL", "Headphone Jack", "HPOR";
		simple-audio-card,widgets = "Microphone", "Mic Jack", "Headphone", "Headphone Jack";

		simple-audio-card,dai-link@0 {
			format = "i2s";

			codec {
				sound-dai = <0xc9 0x00>;
			};

			cpu {
				sound-dai = <0xc8>;
			};
		};

		simple-audio-card,dai-link@1 {
			format = "pdm";

			codec {
				sound-dai = <0xc9 0x01>;
			};

			cpu {
				sound-dai = <0xca>;
			};
		};
	};

	rk_headset {
		compatible = "rockchip_headset";
		headset_gpio = <0x69 0x08 0x01>;
		io-channels = <0xc6 0x01>;
		pinctrl-0 = <0xcb>;
		pinctrl-names = "default";
		status = "disabled";
	};

	rk_isp@ff4a0000 {
		clock-names = "aclk_isp", "hclk_isp", "clk_isp", "clk_isp_jpe", "pclkin_isp", "clk_cif_pll", "clk_cif_out", "pclk_dphyrx";
		clocks = <0x02 0xb4 0x02 0xfa 0x02 0x33 0x02 0x33 0x02 0x15f 0x02 0x34 0x02 0x34 0x02 0x146>;
		compatible = "rockchip,px30-isp", "rockchip,isp";
		interrupts = <0x00 0x46 0x04>;
		iommus = <0xb3>;
		pinctrl-0 = <0x6a>;
		pinctrl-1 = <0xaf>;
		pinctrl-2 = <0xaf 0xb1>;
		pinctrl-3 = <0xb2 0xaf 0xb1>;
		pinctrl-names = "default", "isp_dvp8bit2", "isp_dvp10bit", "isp_dvp12bit";
		power-domains = <0x8c 0x0d>;
		reg = <0x00 0xff4a0000 0x00 0x8000>;
		reset-names = "rst_isp", "rst_mipicsiphy";
		resets = <0x02 0x2b 0x02 0x2f>;
		rockchip,cru = <0x02>;
		rockchip,grf = <0x87>;
		rockchip,isp,csiphy,reg = <0xff2f0000 0x4000>;
		rockchip,isp,iommu-enable = <0x01>;
		rockchip,isp,mipiphy = <0x01>;
		status = "disabled";
	};

	rk_rga@ff480000 {
		clock-names = "aclk_rga", "hclk_rga", "clk_rga";
		clocks = <0x02 0xb7 0x02 0xfd 0x02 0x35>;
		compatible = "rockchip,rga2";
		dma-coherent;
		interrupts = <0x00 0x4c 0x04>;
		power-domains = <0x8c 0x0c>;
		reg = <0x00 0xff480000 0x00 0x1000>;
		status = "okay";
	};

	rkisp1@ff4a0000 {
		clock-names = "aclk_isp", "hclk_isp", "clk_isp", "pclk_isp";
		clocks = <0x02 0xb4 0x02 0xfa 0x02 0x33 0x02 0x15f>;
		compatible = "rockchip,rk3326-rkisp1";
		devfreq = <0xb4>;
		interrupts = <0x00 0x46 0x04>;
		iommus = <0xb3>;
		power-domains = <0x8c 0x0d>;
		reg = <0x00 0xff4a0000 0x00 0x8000>;
		status = "disabled";

		port {
			#address-cells = <0x01>;
			#size-cells = <0x00>;

			endpoint@0 {
				phandle = <0x8f>;
				reg = <0x00>;
				remote-endpoint = <0xb5>;
			};
		};
	};

	rktimer@ff210000 {
		clock-names = "pclk", "timer";
		clocks = <0x02 0x159 0x02 0x26>;
		compatible = "rockchip,rk3288-timer";
		interrupts = <0x00 0x1e 0x04>;
		reg = <0x00 0xff210000 0x00 0x1000>;
	};

	rockchip-suspend {
		compatible = "rockchip,pm-px30";
		rockchip,sleep-debug-en = <0x01>;
		rockchip,sleep-mode-config = <0x20702>;
		rockchip,wakeup-config = <0x85>;
		status = "okay";
	};

	rockchip_wdt {
		clock-names = "pclk_wdt";
		clocks = <0x02 0x15b>;
		compatible = "rockchip,watch dog";
		reg = <0x00 0xff1e0000 0x00 0x18>;
		rockchip,atboot = <0x00>;
		rockchip,debug = <0x00>;
		rockchip,irq = <0x00>;
		rockchip,timeout = <0x0a>;
	};

	saradc@ff288000 {
		#io-channel-cells = <0x01>;
		clock-names = "saradc", "apb_pclk";
		clocks = <0x02 0x2d 0x02 0x157>;
		compatible = "rockchip,px30-saradc", "rockchip,rk3399-saradc";
		interrupts = <0x00 0x54 0x04>;
		phandle = <0xc6>;
		reg = <0x00 0xff288000 0x00 0x100>;
		reset-names = "saradc-apb";
		resets = <0x02 0xa5>;
		status = "okay";
		vref-supply = <0x49>;
	};

	sdio-pwrseq {
		compatible = "mmc-pwrseq-simple";
		phandle = <0x9d>;
		pinctrl-0 = <0xcc>;
		pinctrl-names = "default";
		reset-gpios = <0x5a 0x02 0x01>;
	};

	serial@ff030000 {
		#dma-cells = <0x02>;
		clock-names = "baudclk", "apb_pclk";
		clocks = <0x2b 0x06 0x2b 0x15>;
		compatible = "rockchip,px30-uart", "snps,dw-apb-uart";
		dmas = <0x2c 0x00 0x2c 0x01>;
		interrupts = <0x00 0x0f 0x04>;
		pinctrl-0 = <0x2d 0x2e 0x2f>;
		pinctrl-names = "default";
		reg = <0x00 0xff030000 0x00 0x100>;
		reg-io-width = <0x04>;
		reg-shift = <0x02>;
		status = "disabled";
	};

	serial@ff158000 {
		#dma-cells = <0x02>;
		clock-names = "baudclk", "apb_pclk";
		clocks = <0x02 0x18 0x02 0x149>;
		compatible = "rockchip,px30-uart", "snps,dw-apb-uart";
		dmas = <0x2c 0x02 0x2c 0x03>;
		interrupts = <0x00 0x10 0x04>;
		pinctrl-0 = <0x4d 0x4e>;
		pinctrl-names = "default";
		reg = <0x00 0xff158000 0x00 0x100>;
		reg-io-width = <0x04>;
		reg-shift = <0x02>;
		status = "okay";
	};

	serial@ff160000 {
		#dma-cells = <0x02>;
		clock-names = "baudclk", "apb_pclk";
		clocks = <0x02 0x19 0x02 0x14a>;
		compatible = "rockchip,px30-uart", "snps,dw-apb-uart";
		dmas = <0x2c 0x04 0x2c 0x05>;
		interrupts = <0x00 0x11 0x04>;
		pinctrl-0 = <0x4f>;
		pinctrl-names = "default";
		reg = <0x00 0xff160000 0x00 0x100>;
		reg-io-width = <0x04>;
		reg-shift = <0x02>;
		status = "disabled";
	};

	serial@ff168000 {
		#dma-cells = <0x02>;
		clock-names = "baudclk", "apb_pclk";
		clocks = <0x02 0x1a 0x02 0x14b>;
		compatible = "rockchip,px30-uart", "snps,dw-apb-uart";
		dmas = <0x2c 0x06 0x2c 0x07>;
		interrupts = <0x00 0x12 0x04>;
		pinctrl-0 = <0x50 0x51 0x52>;
		pinctrl-names = "default";
		reg = <0x00 0xff168000 0x00 0x100>;
		reg-io-width = <0x04>;
		reg-shift = <0x02>;
		status = "disabled";
	};

	serial@ff170000 {
		#dma-cells = <0x02>;
		clock-names = "baudclk", "apb_pclk";
		clocks = <0x02 0x1b 0x02 0x14c>;
		compatible = "rockchip,px30-uart", "snps,dw-apb-uart";
		dma-names = "!tx", "!rx";
		dmas = <0x2c 0x08 0x2c 0x09>;
		interrupts = <0x00 0x13 0x04>;
		pinctrl-0 = <0x53 0x54 0x55>;
		pinctrl-names = "default";
		reg = <0x00 0xff170000 0x00 0x100>;
		reg-io-width = <0x04>;
		reg-shift = <0x02>;
		status = "okay";
	};

	serial@ff178000 {
		#dma-cells = <0x02>;
		clock-names = "baudclk", "apb_pclk";
		clocks = <0x02 0x1c 0x02 0x14d>;
		compatible = "rockchip,px30-uart", "snps,dw-apb-uart";
		dmas = <0x2c 0x0a 0x2c 0x0b>;
		interrupts = <0x00 0x14 0x04>;
		pinctrl-0 = <0x56 0x57 0x58>;
		pinctrl-names = "default";
		reg = <0x00 0xff178000 0x00 0x100>;
		reg-io-width = <0x04>;
		reg-shift = <0x02>;
		status = "okay";
	};

	spi@ff1d0000 {
		#address-cells = <0x01>;
		#dma-cells = <0x02>;
		#size-cells = <0x00>;
		clock-names = "spiclk", "apb_pclk";
		clocks = <0x02 0x24 0x02 0x155>;
		compatible = "rockchip,px30-spi", "rockchip,rk3066-spi";
		dma-names = "tx", "rx";
		dmas = <0x2c 0x0c 0x2c 0x0d>;
		interrupts = <0x00 0x1a 0x04>;
		pinctrl-0 = <0x6d 0x6e 0x6f 0x70>;
		pinctrl-1 = <0x71 0x6e 0x72 0x73>;
		pinctrl-names = "default", "high_speed";
		reg = <0x00 0xff1d0000 0x00 0x1000>;
		status = "disabled";
	};

	spi@ff1d8000 {
		#address-cells = <0x01>;
		#dma-cells = <0x02>;
		#size-cells = <0x00>;
		clock-names = "spiclk", "apb_pclk";
		clocks = <0x02 0x25 0x02 0x156>;
		compatible = "rockchip,px30-spi", "rockchip,rk3066-spi";
		dma-names = "tx", "rx";
		dmas = <0x2c 0x0e 0x2c 0x0f>;
		interrupts = <0x00 0x1b 0x04>;
		pinctrl-0 = <0x74 0x75 0x76 0x77 0x78>;
		pinctrl-1 = <0x79 0x75 0x76 0x7a 0x7b>;
		pinctrl-names = "default", "high_speed";
		reg = <0x00 0xff1d8000 0x00 0x1000>;
		status = "disabled";
	};

	syscon@ff010000 {
		#address-cells = <0x01>;
		#size-cells = <0x01>;
		compatible = "rockchip,px30-pmugrf", "syscon", "simple-mfd";
		phandle = <0xb6>;
		reg = <0x00 0xff010000 0x00 0x1000>;

		io-domains {
			compatible = "rockchip,px30-pmu-io-voltage-domain";
			pmuio1-supply = <0x2a>;
			pmuio2-supply = <0x2a>;
			status = "okay";
		};

		pmu-pvtm {
			clock-names = "pmu";
			clocks = <0x2b 0x07>;
			compatible = "rockchip,px30-pmu-pvtm";
			status = "okay";
		};

		reboot-mode {
			compatible = "syscon-reboot-mode";
			mode-bootloader = <0x5242c301>;
			mode-charge = <0x5242c30b>;
			mode-fastboot = <0x5242c309>;
			mode-loader = <0x5242c301>;
			mode-normal = <0x5242c300>;
			mode-recovery = <0x5242c303>;
			mode-ums = <0x5242c30c>;
			offset = <0x200>;
		};
	};

	syscon@ff140000 {
		#address-cells = <0x01>;
		#size-cells = <0x01>;
		compatible = "rockchip,px30-grf", "syscon", "simple-mfd";
		phandle = <0x87>;
		reg = <0x00 0xff140000 0x00 0x1000>;

		io-domains {
			compatible = "rockchip,px30-io-voltage-domain";
			status = "okay";
			vccio1-supply = <0x49>;
			vccio2-supply = <0x4a>;
			vccio3-supply = <0x4b>;
			vccio4-supply = <0x2a>;
			vccio5-supply = <0x4b>;
		};

		rgb {
			compatible = "rockchip,px30-rgb";
			status = "disabled";

			ports {
				#address-cells = <0x01>;
				#size-cells = <0x00>;

				port@0 {
					#address-cells = <0x01>;
					#size-cells = <0x00>;
					reg = <0x00>;

					endpoint@0 {
						phandle = <0xaa>;
						reg = <0x00>;
						remote-endpoint = <0x15>;
					};

					endpoint@1 {
						phandle = <0xae>;
						reg = <0x01>;
						remote-endpoint = <0x4c>;
					};
				};
			};
		};
	};

	syscon@ff148000 {
		#address-cells = <0x01>;
		#size-cells = <0x01>;
		compatible = "syscon", "simple-mfd";
		reg = <0x00 0xff148000 0x00 0x1000>;

		pvtm {
			clock-names = "core";
			clocks = <0x02 0x4a>;
			compatible = "rockchip,px30-pvtm";
			status = "okay";
		};
	};

	syscon@ff2c0000 {
		#address-cells = <0x01>;
		#size-cells = <0x01>;
		compatible = "rockchip,px30-usb2phy-grf", "syscon", "simple-mfd";
		reg = <0x00 0xff2c0000 0x00 0x10000>;

		usb2-phy@100 {
			#clock-cells = <0x00>;
			assigned-clock-parents = <0x8b 0x02 0x0e>;
			assigned-clocks = <0x02 0x0e 0x02 0x55>;
			clock-names = "phyclk";
			clock-output-names = "usb480m_phy";
			clocks = <0x2b 0x0a>;
			compatible = "rockchip,px30-usb2phy", "rockchip,rk3328-usb2phy";
			phandle = <0x8b>;
			reg = <0x100 0x10>;
			status = "okay";

			host-port {
				#phy-cells = <0x00>;
				interrupt-names = "linestate";
				interrupts = <0x00 0x44 0x04>;
				phandle = <0x91>;
				status = "okay";
			};

			otg-port {
				#phy-cells = <0x00>;
				interrupt-names = "otg-bvalid", "otg-id", "linestate";
				interrupts = <0x00 0x42 0x04 0x00 0x41 0x04 0x00 0x40 0x04>;
				phandle = <0x90>;
				status = "okay";
			};
		};
	};

	thermal-zones {

		gpu-thermal {
			polling-delay = <0x3e8>;
			polling-delay-passive = <0x64>;
			thermal-sensors = <0x84 0x01>;
		};

		soc-thermal {
			polling-delay = <0x3e8>;
			polling-delay-passive = <0x14>;
			sustainable-power = <0x2ee>;
			thermal-sensors = <0x84 0x00>;

			cooling-maps {

				map0 {
					contribution = <0x1000>;
					cooling-device = <0x09 0xffffffff 0xffffffff>;
					trip = <0x85>;
				};

				map1 {
					contribution = <0x1000>;
					cooling-device = <0x86 0xffffffff 0xffffffff>;
					trip = <0x85>;
				};
			};

			trips {

				soc-crit {
					hysteresis = <0x7d0>;
					temperature = <0x1c138>;
					type = "critical";
				};

				trip-point-0 {
					hysteresis = <0x7d0>;
					temperature = <0x11170>;
					type = "passive";
				};

				trip-point-1 {
					hysteresis = <0x7d0>;
					phandle = <0x85>;
					temperature = <0x14c08>;
					type = "passive";
				};
			};
		};
	};

	timer {
		compatible = "arm,armv8-timer";
		interrupts = <0x01 0x0d 0xf04 0x01 0x0e 0xf04 0x01 0x0b 0xf04 0x01 0x0a 0xf04>;
	};

	tsadc@ff280000 {
		#thermal-sensor-cells = <0x01>;
		assigned-clock-rates = <0xc350>;
		assigned-clocks = <0x02 0x2c>;
		clock-names = "tsadc", "apb_pclk";
		clocks = <0x02 0x2c 0x02 0x158>;
		compatible = "rockchip,px30-tsadc";
		interrupts = <0x00 0x24 0x04>;
		phandle = <0x84>;
		pinctrl-0 = <0x88>;
		pinctrl-1 = <0x89>;
		pinctrl-names = "init", "default";
		reg = <0x00 0xff280000 0x00 0x100>;
		reset-names = "tsadc-apb";
		resets = <0x02 0xa8>;
		rockchip,grf = <0x87>;
		rockchip,hw-tshut-temp = <0x1d4c0>;
		status = "okay";
	};

	twi.1 {
		compatible = "px30-cht_plat";
		status = "okay";
	};

	usb@ff300000 {
		clock-names = "otg";
		clocks = <0x02 0x102>;
		compatible = "rockchip,px30-usb", "rockchip,rk3066-usb", "snps,dwc2";
		dr_mode = "otg";
		g-np-tx-fifo-size = <0x10>;
		g-rx-fifo-size = <0x118>;
		g-tx-fifo-size = <0x100 0x80 0x80 0x40 0x20 0x10>;
		g-use-dma;
		interrupts = <0x00 0x3e 0x04>;
		phy-names = "usb2-phy";
		phys = <0x90>;
		power-domains = <0x8c 0x05>;
		reg = <0x00 0xff300000 0x00 0x40000>;
		status = "okay";
	};

	usb@ff340000 {
		clock-names = "usbhost", "utmi";
		clocks = <0x02 0x103 0x8b>;
		compatible = "generic-ehci";
		interrupts = <0x00 0x3c 0x04>;
		phy-names = "usb";
		phys = <0x91>;
		power-domains = <0x8c 0x05>;
		reg = <0x00 0xff340000 0x00 0x10000>;
		status = "okay";
	};

	usb@ff350000 {
		clock-names = "usbhost", "utmi";
		clocks = <0x02 0x103 0x8b>;
		compatible = "generic-ohci";
		interrupts = <0x00 0x3d 0x04>;
		phy-names = "usb";
		phys = <0x91>;
		power-domains = <0x8c 0x05>;
		reg = <0x00 0xff350000 0x00 0x10000>;
		status = "okay";
	};

	vcc-phy-regulator {
		compatible = "regulator-fixed";
		phandle = <0x94>;
		regulator-always-on;
		regulator-boot-on;
		regulator-name = "vcc_phy";
	};

	vccsys {
		compatible = "regulator-fixed";
		phandle = <0x62>;
		regulator-always-on;
		regulator-boot-on;
		regulator-max-microvolt = <0x4c4b40>;
		regulator-min-microvolt = <0x4c4b40>;
		regulator-name = "vcc5v0_sys";
	};

	vop@ff460000 {
		clock-names = "aclk_vop", "dclk_vop", "hclk_vop";
		clocks = <0x02 0xb5 0x02 0x96 0x02 0xfb>;
		compatible = "rockchip,px30-vop-big";
		interrupts = <0x00 0x4d 0x04>;
		iommus = <0xa7>;
		power-domains = <0x8c 0x0c>;
		reg = <0x00 0xff460000 0x00 0x1fc 0x00 0xff460a00 0x00 0x400>;
		reg-names = "regs", "gamma_lut";
		rockchip,grf = <0x87>;
		status = "okay";

		port {
			#address-cells = <0x01>;
			#size-cells = <0x00>;
			phandle = <0x10>;

			endpoint@0 {
				phandle = <0x13>;
				reg = <0x00>;
				remote-endpoint = <0xa8>;
			};

			endpoint@1 {
				phandle = <0x14>;
				reg = <0x01>;
				remote-endpoint = <0xa9>;
			};

			endpoint@2 {
				phandle = <0x15>;
				reg = <0x02>;
				remote-endpoint = <0xaa>;
			};
		};
	};

	vop@ff470000 {
		clock-names = "aclk_vop", "dclk_vop", "hclk_vop";
		clocks = <0x02 0xb6 0x02 0x97 0x02 0xfc>;
		compatible = "rockchip,px30-vop-lit";
		interrupts = <0x00 0x4e 0x04>;
		iommus = <0xab>;
		power-domains = <0x8c 0x0c>;
		reg = <0x00 0xff470000 0x00 0x1fc 0x00 0xff470a00 0x00 0x400>;
		reg-names = "regs", "gamma_lut";
		rockchip,grf = <0x87>;
		status = "okay";

		port {
			#address-cells = <0x01>;
			#size-cells = <0x00>;
			phandle = <0x11>;

			endpoint@0 {
				phandle = <0x8d>;
				reg = <0x00>;
				remote-endpoint = <0xac>;
			};

			endpoint@1 {
				phandle = <0xa4>;
				reg = <0x01>;
				remote-endpoint = <0xad>;
			};

			endpoint@2 {
				phandle = <0x4c>;
				reg = <0x02>;
				remote-endpoint = <0xae>;
			};
		};
	};

	vpu_combo {
		clock-names = "aclk_vcodec", "hclk_vcodec", "clk_core";
		clocks = <0x02 0xaf 0x02 0xf4 0x02 0x4b>;
		compatible = "rockchip,vpu_combo";
		mode_bit = <0x0f>;
		mode_ctrl = <0x410>;
		power-domains = <0x8c 0x0b>;
		reset-names = "video_a", "video_h", "niu_a", "niu_h", "video_core";
		resets = <0x02 0x24 0x02 0x26 0x02 0x25 0x02 0x27 0x02 0x3f>;
		rockchip,grf = <0x87>;
		rockchip,sub = <0xa1 0xa2>;
		status = "okay";
		subcnt = <0x02>;
	};

	vpu_service@ff442000 {
		allocator = <0x01>;
		compatible = "rockchip,vpu_sub";
		dev_mode = <0x00>;
		interrupt-names = "irq_enc", "irq_dec";
		interrupts = <0x00 0x50 0x04 0x00 0x4f 0x04>;
		iommu_enabled = <0x01>;
		iommus = <0xa0>;
		phandle = <0xa1>;
		reg = <0x00 0xff442000 0x00 0x800>;
	};

	watchdog@ff1e0000 {
		clocks = <0x02 0x15b>;
		compatible = "snps,dw-wdt";
		interrupts = <0x00 0x25 0x04>;
		reg = <0x00 0xff1e0000 0x00 0x100>;
		status = "disabled";
	};

	wireless-bluetooth {
		BT,reset_gpio = <0x5a 0x11 0x00>;
		BT,wake_gpio = <0x5a 0x01 0x00>;
		BT,wake_host_irq = <0x5a 0x0a 0x00>;
		clock-names = "ext_clock";
		clocks = <0xcd 0x01>;
		compatible = "bluetooth-platdata";
		pinctrl-0 = <0xcf>;
		pinctrl-1 = <0xd0>;
		pinctrl-names = "default", "rts_gpio";
		status = "okay";
		uart_rts_gpios = <0xce 0x13 0x01>;
	};

	wireless-wlan {
		WIFI,host_wake_irq = <0x5a 0x05 0x00>;
		compatible = "wlan-platdata";
		status = "okay";
		wifi_chip_type = "RTL8723DS";
	};

	xin24m {
		#clock-cells = <0x00>;
		clock-frequency = <0x16e3600>;
		clock-output-names = "xin24m";
		compatible = "fixed-clock";
	};

	xin32k {
		#clock-cells = <0x00>;
		clock-frequency = <0x8000>;
		clock-output-names = "xin32k";
		compatible = "fixed-clock";
	};
};
